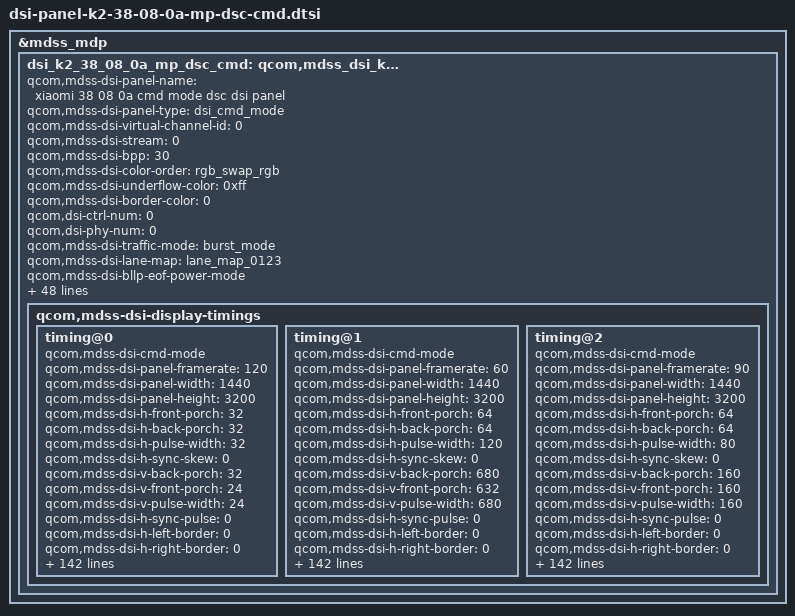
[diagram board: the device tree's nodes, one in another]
&mdss_mdp {
	dsi_k2_38_08_0a_mp_dsc_cmd: qcom,mdss_dsi_k2_38_08_0a_mp_dsc_cmd {
		qcom,mdss-dsi-panel-name = "xiaomi 38 08 0a cmd mode dsc dsi panel";
		qcom,mdss-dsi-panel-type = "dsi_cmd_mode";
		qcom,mdss-dsi-virtual-channel-id = <0>;
		qcom,mdss-dsi-stream = <0>;
		qcom,mdss-dsi-bpp = <30>;
		qcom,mdss-dsi-color-order = "rgb_swap_rgb";
		qcom,mdss-dsi-underflow-color = <0xff>;
		qcom,mdss-dsi-border-color = <0>;

		qcom,dsi-ctrl-num = <0>;
		qcom,dsi-phy-num = <0>;

		qcom,mdss-dsi-traffic-mode = "burst_mode";
		qcom,mdss-dsi-lane-map = "lane_map_0123";
		qcom,mdss-dsi-bllp-eof-power-mode;
		qcom,mdss-dsi-bllp-power-mode;
		qcom,mdss-dsi-lane-0-state;
		qcom,mdss-dsi-lane-1-state;
		qcom,mdss-dsi-lane-2-state;
		qcom,mdss-dsi-lane-3-state;
		qcom,mdss-dsi-dma-trigger = "trigger_sw";
		qcom,mdss-dsi-mdp-trigger = "none";
		qcom,mdss-dsi-reset-sequence = <0 10>, <1 10>;
		qcom,mdss-pan-physical-width-dimension = <710>;
		qcom,mdss-pan-physical-height-dimension = <1578>;
		qcom,mdss-dsi-te-pin-select = <1>;
		qcom,mdss-dsi-wr-mem-start = <0x2c>;
		qcom,mdss-dsi-wr-mem-continue = <0x3c>;
		qcom,mdss-dsi-te-dcs-command = <1>;
		qcom,mdss-dsi-te-check-enable;
		qcom,mdss-dsi-te-using-te-pin;
		qcom,mdss-dsi-tx-eot-append;
		qcom,mdss-dsi-lp11-init;

		qcom,mdss-dsi-panel-mode-switch;

		qcom,mdss-dsi-bl-inverted-dbv;
		qcom,bl-update-flag = "delay_until_first_frame";

		qcom,mdss-dsi-panel-hdr-enabled;
		qcom,mdss-dsi-panel-hdr-color-primaries = <14500 15500 32000
			17000 15500 30000 8000 3000>;
		qcom,mdss-dsi-panel-peak-brightness = <4200000>;
		qcom,mdss-dsi-panel-blackness-level = <3230>;

		qcom,mdss-dsi-display-timings {
			timing@0{
				qcom,mdss-dsi-cmd-mode;
				qcom,mdss-dsi-panel-framerate = <120>;
				qcom,mdss-dsi-panel-width = <1440>;
				qcom,mdss-dsi-panel-height = <3200>;
				qcom,mdss-dsi-h-front-porch = <32>;
				qcom,mdss-dsi-h-back-porch = <32>;
				qcom,mdss-dsi-h-pulse-width = <32>;
				qcom,mdss-dsi-h-sync-skew = <0>;
				qcom,mdss-dsi-v-back-porch = <32>;
				qcom,mdss-dsi-v-front-porch = <24>;
				qcom,mdss-dsi-v-pulse-width = <24>;
				qcom,mdss-dsi-h-sync-pulse = <0>;
				qcom,mdss-dsi-h-left-border = <0>;
				qcom,mdss-dsi-h-right-border = <0>;
				qcom,mdss-dsi-v-top-border = <0>;
				qcom,mdss-dsi-v-bottom-border = <0>;
				qcom,mdss-dsi-panel-clockrate = <1360000000>;
				qcom,mdss-dsi-panel-jitter = <0x5 0x1>;
				qcom,mdss-mdp-transfer-time-us = <6800>;
				qcom,mdss-dsi-on-command = [
					/* 1 DSC Setting */
					15 01 00 00 00 00 02 9D 01                           /* Compression Enable */
					39 01 00 00 00 00 81 9E                              /* PPS Setting */
					11 00 00 A9 30 80 0C 80
					05 A0 00 32 02 D0 02 D0
					02 00 02 68 00 20 05 8C
					00 0A 00 0C 01 F6 01 87
					18 00 10 F0 03 0C 20 00
					06 0B 0B 33 0E 1C 2A 38
					46 54 62 69 70 77 79 7B
					7D 7E 01 02 01 00 09 40
					09 BE 19 FC 19 FA 19 F8
					1A 38 1A 78 1A B6 2A F6
					2B 34 2B 74 3B 74 6B F4
					00 00 00 00 00 00 00 00
					00 00 00 00 00 00 00 00
					00 00 00 00 00 00 00 00
					00 00 00 00 00 00 00 00
					00 00 00 00 00 00 00 00
					/* 2 Sleep Out */
					05 01 00 00 0A 00 02 11 00                           /* Sleep Out */
					/* 3 Common Setting */
					/* 3.1 TE(Vsync) On/Off */
					15 01 00 00 00 00 02 35 00                           /* TE On(Vsync) */
					/* 3.2 CASET/PASET Setting */
					39 01 00 00 00 00 05 2A 00 00 05 9F                  /* CASET 1440*/
					39 01 00 00 00 00 05 2B 00 00 0C 7F                  /* PASET 3200*/
					/* 4.3 11Bit Dimming Setting */
					39 01 00 00 00 00 03 F0 5A 5A
					15 01 00 00 00 00 02 B0 01                           /* Global para */
					15 01 00 00 00 00 02 B4 01                           /* 11Bit Dimming On*/
					15 01 00 00 00 00 02 F7 07                           /* Update Key*/
					39 01 00 00 00 00 03 F0 A5 A5
					/* 4.8 Err FG Setting*/
					39 01 00 00 00 00 03 F0 5A 5A
					15 01 00 00 00 00 02 B0 02
					39 01 00 00 00 00 05 F4 00 C0 7F 3D
					15 01 00 00 00 00 02 B0 09
					15 01 00 00 00 00 02 F4 07
					15 01 00 00 00 00 02 B0 11
					15 01 00 00 00 00 02 F4 19
					39 01 00 00 00 00 03 F0 A5 A5
					/* AOD Setting*/
					39 01 00 00 00 00 03 F0 5A 5A
					15 01 00 00 00 00 02 B0 04
					15 01 00 00 00 00 02 EE 80
					15 01 00 00 00 00 02 B0 C0
					15 01 00 00 00 00 02 D6 40
					39 01 00 00 00 00 03 F0 A5 A5
					/* 4.10 Pentile Setting*/
					39 01 00 00 00 00 03 F0 5A 5A
					39 01 00 00 00 00 08 B3 00 00 D8 D8 FF FF 40         /* 2D Rendering */
					39 01 00 00 00 00 03 F0 A5 A5
					/* DCDC SET PIN LOW*/
					39 01 00 00 00 00 03 F0 5A 5A
					15 01 00 00 00 00 02 E7 81
					15 01 00 00 00 00 02 B0 09
					15 01 00 00 00 00 02 E7 03
					39 01 00 00 00 00 03 F0 A5 A5
					/* SRAM ECC ON*/
					39 01 00 00 00 00 03 F0 5A 5A
					39 01 00 00 00 00 03 FC 5A 5A
					39 01 00 00 00 00 02 B0 0F
					39 01 00 00 00 00 02 E1 10
					/* OPEC IP Bypass*/
					39 01 00 00 00 00 02 CF 01
					39 01 00 00 00 00 03 FC A5 A5
					39 01 00 00 00 00 03 F0 A5 A5
					/* 4.11 Power Saving Setting*/
					39 01 00 00 00 00 03 F0 5A 5A
					39 01 00 00 00 00 03 FC 5A 5A
					15 01 00 00 00 00 02 B0 76
					15 01 00 00 00 00 02 D1 01
					15 01 00 00 00 00 02 B0 22
					39 01 00 00 00 00 04 E2 01 02 25
					15 01 00 00 00 00 02 F7 07
					39 01 00 00 00 00 03 FC A5 A5
					39 01 00 00 5A 00 03 F0 A5 A5
					/* Dimming Setting*/
					39 01 00 00 00 00 03 F0 5A 5A
					15 01 00 00 00 00 02 B0 0D                           /* Global para */
					15 01 00 00 00 00 02 B4 20                           /* Dimming Speed Setting : 0x20 : 32Frames*/
					15 01 00 00 00 00 02 B0 0C                           /* Global para */
					15 01 00 00 00 00 02 B4 20                           /* 0x20 : ELVSS DIM OFF */
					15 01 00 00 00 00 02 53 20                           /* 0x20 Normal transition(60Hz) */
					39 01 00 00 00 00 03 51 00 00                        /* Write Display Brightness */
					15 01 00 00 00 00 02 F7 07
					39 01 00 00 00 00 03 F0 A5 A5
					/* OFC (MIPI 1360Mbps/Lane, OSC 165Mhz)*/
					39 01 00 00 00 00 03 F0 5A 5A
					39 01 00 00 00 00 03 FC 5A 5A
					15 01 00 00 00 00 02 B0 07
					39 01 00 00 00 00 04 EB 03 88 F8
					39 01 00 00 00 00 03 FC A5 A5
					39 01 00 00 00 00 03 F0 A5 A5
					/* 5 Display On */
					05 01 00 00 11 00 02 29 00
					/* 120hz Frequency Select*/
					15 01 00 00 00 00 02 60 08
					39 01 00 00 00 00 03 F0 5A 5A
					39 01 00 00 00 00 03 FC 5A 5A
					15 01 00 00 00 00 02 B0 55
					15 01 00 00 00 00 02 D1 0E
					15 01 00 00 00 00 02 F7 07
					39 01 00 00 00 00 03 FC A5 A5
					39 01 00 00 00 00 03 F0 A5 A5];
				qcom,mdss-dsi-off-command = [
					39 00 00 00 00 00 03 F0 5A 5A
					39 00 00 00 00 00 03 FC 5A 5A
					15 00 00 00 00 00 02 60 08
					15 00 00 00 00 00 02 B0 55
					15 00 00 00 00 00 02 D1 0E
					15 00 00 00 00 00 02 53 28
					15 00 00 00 00 00 02 F7 07
					39 00 00 00 00 00 03 FC A5 A5
					39 01 00 00 00 00 03 F0 A5 A5
					05 01 00 00 22 00 02 28 00
					05 01 00 00 78 00 02 10 00];
				qcom,mdss-dsi-on-command-state = "dsi_lp_mode";
				qcom,mdss-dsi-off-command-state = "dsi_lp_mode";

				qcom,mdss-dsi-timing-switch-command = [
					15 00 00 00 00 00 02 60 08
					39 00 00 00 00 00 03 F0 5A 5A
					39 00 00 00 00 00 03 FC 5A 5A
					15 00 00 00 00 00 02 B0 55
					15 00 00 00 00 00 02 D1 0E
					15 00 00 00 00 00 02 F7 07
					39 00 00 00 00 00 03 FC A5 A5
					39 01 00 00 00 00 03 F0 A5 A5];
				qcom,mdss-dsi-timing-switch-command-state = "dsi_lp_mode";

				qcom,mdss-dsi-nolp-command = [
					39 01 00 00 00 00 03 F0 5A 5A
					39 01 00 00 00 00 03 FC 5A 5A
					15 00 00 00 00 00 02 60 08
					15 00 00 00 00 00 02 B0 55
					15 00 00 00 00 00 02 D1 0E
					15 00 00 00 00 00 02 53 28
					15 01 00 00 00 00 02 F7 07
					39 01 00 00 00 00 03 FC A5 A5
					39 01 00 00 09 00 03 F0 A5 A5
				];
				qcom,mdss-dsi-nolp-command-state = "dsi_lp_mode";

				qcom,compression-mode = "dsc";
				qcom,mdss-dsc-slice-height = <50>;
				qcom,mdss-dsc-slice-width = <720>;
				qcom,mdss-dsc-slice-per-pkt = <2>;
				qcom,mdss-dsc-bit-per-component = <10>;
				qcom,mdss-dsc-bit-per-pixel = <8>;
				qcom,mdss-dsc-block-prediction-enable;
			};

			timing@1{
				qcom,mdss-dsi-cmd-mode;
				qcom,mdss-dsi-panel-framerate = <60>;
				qcom,mdss-dsi-panel-width = <1440>;
				qcom,mdss-dsi-panel-height = <3200>;
				qcom,mdss-dsi-h-front-porch = <64>;
				qcom,mdss-dsi-h-back-porch = <64>;
				qcom,mdss-dsi-h-pulse-width = <120>;
				qcom,mdss-dsi-h-sync-skew = <0>;
				qcom,mdss-dsi-v-back-porch = <680>;
				qcom,mdss-dsi-v-front-porch = <632>;
				qcom,mdss-dsi-v-pulse-width = <680>;
				qcom,mdss-dsi-h-sync-pulse = <0>;
				qcom,mdss-dsi-h-left-border = <0>;
				qcom,mdss-dsi-h-right-border = <0>;
				qcom,mdss-dsi-v-top-border = <0>;
				qcom,mdss-dsi-v-bottom-border = <0>;
				qcom,mdss-dsi-panel-clockrate = <1360000000>;
				qcom,mdss-dsi-panel-jitter = <0x5 0x1>;
				qcom,mdss-mdp-transfer-time-us = <14000>;
				qcom,mdss-dsi-on-command = [
					/* 1 DSC Setting */
					15 01 00 00 00 00 02 9D 01                           /* Compression Enable */
					39 01 00 00 00 00 81 9E                              /* PPS Setting */
					11 00 00 A9 30 80 0C 80
					05 A0 00 32 02 D0 02 D0
					02 00 02 68 00 20 05 8C
					00 0A 00 0C 01 F6 01 87
					18 00 10 F0 03 0C 20 00
					06 0B 0B 33 0E 1C 2A 38
					46 54 62 69 70 77 79 7B
					7D 7E 01 02 01 00 09 40
					09 BE 19 FC 19 FA 19 F8
					1A 38 1A 78 1A B6 2A F6
					2B 34 2B 74 3B 74 6B F4
					00 00 00 00 00 00 00 00
					00 00 00 00 00 00 00 00
					00 00 00 00 00 00 00 00
					00 00 00 00 00 00 00 00
					00 00 00 00 00 00 00 00
					/* 2 Sleep Out */
					05 01 00 00 0A 00 02 11 00                           /* Sleep Out */
					/* 3 Common Setting */
					/* 3.1 TE(Vsync) On/Off */
					15 01 00 00 00 00 02 35 00                           /* TE On(Vsync) */
					/* 3.2 CASET/PASET Setting */
					39 01 00 00 00 00 05 2A 00 00 05 9F                  /* CASET 1440*/
					39 01 00 00 00 00 05 2B 00 00 0C 7F                  /* PASET 3200*/
					/* 4.3 11Bit Dimming Setting */
					39 01 00 00 00 00 03 F0 5A 5A
					15 01 00 00 00 00 02 B0 01                           /* Global para */
					15 01 00 00 00 00 02 B4 01                           /* 11Bit Dimming On*/
					15 01 00 00 00 00 02 F7 07                           /* Update Key*/
					39 01 00 00 00 00 03 F0 A5 A5
					/* 4.8 Err FG Setting*/
					39 01 00 00 00 00 03 F0 5A 5A
					15 01 00 00 00 00 02 B0 02
					39 01 00 00 00 00 05 F4 00 C0 7F 3D
					15 01 00 00 00 00 02 B0 09
					15 01 00 00 00 00 02 F4 07
					15 01 00 00 00 00 02 B0 11
					15 01 00 00 00 00 02 F4 19
					39 01 00 00 00 00 03 F0 A5 A5
					/* AOD Setting*/
					39 01 00 00 00 00 03 F0 5A 5A
					15 01 00 00 00 00 02 B0 04
					15 01 00 00 00 00 02 EE 80
					15 01 00 00 00 00 02 B0 C0
					15 01 00 00 00 00 02 D6 40
					39 01 00 00 00 00 03 F0 A5 A5
					/* 4.10 Pentile Setting*/
					39 01 00 00 00 00 03 F0 5A 5A
					39 01 00 00 00 00 08 B3 00 00 D8 D8 FF FF 40         /* 2D Rendering */
					39 01 00 00 00 00 03 F0 A5 A5
					/* DCDC SET PIN LOW*/
					39 01 00 00 00 00 03 F0 5A 5A
					15 01 00 00 00 00 02 E7 81
					15 01 00 00 00 00 02 B0 09
					15 01 00 00 00 00 02 E7 03
					39 01 00 00 00 00 03 F0 A5 A5
					/* SRAM ECC ON*/
					39 01 00 00 00 00 03 F0 5A 5A
					39 01 00 00 00 00 03 FC 5A 5A
					39 01 00 00 00 00 02 B0 0F
					39 01 00 00 00 00 02 E1 10
					/* OPEC IP Bypass*/
					39 01 00 00 00 00 02 CF 01
					39 01 00 00 00 00 03 FC A5 A5
					39 01 00 00 00 00 03 F0 A5 A5
					/* 4.11 Power Saving Setting*/
					39 01 00 00 00 00 03 F0 5A 5A
					39 01 00 00 00 00 03 FC 5A 5A
					15 01 00 00 00 00 02 B0 76
					15 01 00 00 00 00 02 D1 01
					15 01 00 00 00 00 02 B0 22
					39 01 00 00 00 00 04 E2 01 02 25
					15 01 00 00 00 00 02 F7 07
					39 01 00 00 00 00 03 FC A5 A5
					39 01 00 00 5A 00 03 F0 A5 A5
					/* Dimming Setting*/
					39 01 00 00 00 00 03 F0 5A 5A
					15 01 00 00 00 00 02 B0 0D                           /* Global para */
					15 01 00 00 00 00 02 B4 20                           /* Dimming Speed Setting : 0x20 : 32Frames*/
					15 01 00 00 00 00 02 B0 0C                           /* Global para */
					15 01 00 00 00 00 02 B4 20                           /* 0x20 : ELVSS DIM OFF */
					15 01 00 00 00 00 02 53 20                           /* 0x20 Normal transition(60Hz) */
					39 01 00 00 00 00 03 51 00 00                        /* Write Display Brightness */
					15 01 00 00 00 00 02 F7 07
					39 01 00 00 00 00 03 F0 A5 A5
					/* OFC (MIPI 1360Mbps/Lane, OSC 165Mhz)*/
					39 01 00 00 00 00 03 F0 5A 5A
					39 01 00 00 00 00 03 FC 5A 5A
					15 01 00 00 00 00 02 B0 07
					39 01 00 00 00 00 04 EB 03 88 F8
					39 01 00 00 00 00 03 FC A5 A5
					39 01 00 00 00 00 03 F0 A5 A5
					/* 5 Display On */
					05 01 00 00 11 00 02 29 00
					/* 60hz Frequency Select*/
					15 01 00 00 00 00 02 60 00
					39 01 00 00 00 00 03 F0 5A 5A
					39 01 00 00 00 00 03 FC 5A 5A
					15 01 00 00 00 00 02 B0 55
					15 01 00 00 00 00 02 D1 0E
					15 01 00 00 00 00 02 F7 07
					39 01 00 00 00 00 03 FC A5 A5
					39 01 00 00 00 00 03 F0 A5 A5];
				qcom,mdss-dsi-off-command = [
					39 00 00 00 00 00 03 F0 5A 5A
					39 00 00 00 00 00 03 FC 5A 5A
					15 00 00 00 00 00 02 60 00
					15 00 00 00 00 00 02 B0 55
					15 00 00 00 00 00 02 D1 0E
					15 00 00 00 00 00 02 53 28
					15 00 00 00 00 00 02 F7 07
					39 00 00 00 00 00 03 FC A5 A5
					39 01 00 00 00 00 03 F0 A5 A5
					05 01 00 00 22 00 02 28 00
					05 01 00 00 78 00 02 10 00];
				qcom,mdss-dsi-on-command-state = "dsi_lp_mode";
				qcom,mdss-dsi-off-command-state = "dsi_lp_mode";

				qcom,mdss-dsi-timing-switch-command = [
					15 00 00 00 00 00 02 60 00
					39 00 00 00 00 00 03 F0 5A 5A
					39 00 00 00 00 00 03 FC 5A 5A
					15 00 00 00 00 00 02 B0 55
					15 00 00 00 00 00 02 D1 0E
					15 00 00 00 00 00 02 F7 07
					39 00 00 00 00 00 03 FC A5 A5
					39 01 00 00 11 00 03 F0 A5 A5];
				qcom,mdss-dsi-timing-switch-command-state = "dsi_lp_mode";

				qcom,mdss-dsi-nolp-command = [
					39 01 00 00 00 00 03 F0 5A 5A
					39 01 00 00 00 00 03 FC 5A 5A
					15 00 00 00 00 00 02 60 00
					15 00 00 00 00 00 02 B0 55
					15 00 00 00 00 00 02 D1 0E
					15 00 00 00 00 00 02 53 28
					15 01 00 00 00 00 02 F7 07
					39 01 00 00 00 00 03 FC A5 A5
					39 01 00 00 09 00 03 F0 A5 A5
				];
				qcom,mdss-dsi-nolp-command-state = "dsi_lp_mode";

				qcom,compression-mode = "dsc";
				qcom,mdss-dsc-slice-height = <50>;
				qcom,mdss-dsc-slice-width = <720>;
				qcom,mdss-dsc-slice-per-pkt = <2>;
				qcom,mdss-dsc-bit-per-component = <10>;
				qcom,mdss-dsc-bit-per-pixel = <8>;
				qcom,mdss-dsc-block-prediction-enable;
			};

			timing@2{
				qcom,mdss-dsi-cmd-mode;
				qcom,mdss-dsi-panel-framerate = <90>;
				qcom,mdss-dsi-panel-width = <1440>;
				qcom,mdss-dsi-panel-height = <3200>;
				qcom,mdss-dsi-h-front-porch = <64>;
				qcom,mdss-dsi-h-back-porch = <64>;
				qcom,mdss-dsi-h-pulse-width = <80>;
				qcom,mdss-dsi-h-sync-skew = <0>;
				qcom,mdss-dsi-v-back-porch = <160>;
				qcom,mdss-dsi-v-front-porch = <160>;
				qcom,mdss-dsi-v-pulse-width = <160>;
				qcom,mdss-dsi-h-sync-pulse = <0>;
				qcom,mdss-dsi-h-left-border = <0>;
				qcom,mdss-dsi-h-right-border = <0>;
				qcom,mdss-dsi-v-top-border = <0>;
				qcom,mdss-dsi-v-bottom-border = <0>;
				qcom,mdss-dsi-panel-clockrate = <1360000000>;
				qcom,mdss-dsi-panel-jitter = <0x5 0x1>;
				qcom,mdss-mdp-transfer-time-us = <9500>;
				qcom,mdss-dsi-on-command = [
					/* 1 DSC Setting */
					15 01 00 00 00 00 02 9D 01                           /* Compression Enable */
					39 01 00 00 00 00 81 9E                              /* PPS Setting */
					11 00 00 A9 30 80 0C 80
					05 A0 00 32 02 D0 02 D0
					02 00 02 68 00 20 05 8C
					00 0A 00 0C 01 F6 01 87
					18 00 10 F0 03 0C 20 00
					06 0B 0B 33 0E 1C 2A 38
					46 54 62 69 70 77 79 7B
					7D 7E 01 02 01 00 09 40
					09 BE 19 FC 19 FA 19 F8
					1A 38 1A 78 1A B6 2A F6
					2B 34 2B 74 3B 74 6B F4
					00 00 00 00 00 00 00 00
					00 00 00 00 00 00 00 00
					00 00 00 00 00 00 00 00
					00 00 00 00 00 00 00 00
					00 00 00 00 00 00 00 00
					/* 2 Sleep Out */
					05 01 00 00 0A 00 02 11 00                           /* Sleep Out */
					/* 3 Common Setting */
					/* 3.1 TE(Vsync) On/Off */
					15 01 00 00 00 00 02 35 00                           /* TE On(Vsync) */
					/* 3.2 CASET/PASET Setting */
					39 01 00 00 00 00 05 2A 00 00 05 9F                  /* CASET 1440*/
					39 01 00 00 00 00 05 2B 00 00 0C 7F                  /* PASET 3200*/
					/* 4.3 11Bit Dimming Setting */
					39 01 00 00 00 00 03 F0 5A 5A
					15 01 00 00 00 00 02 B0 01                           /* Global para */
					15 01 00 00 00 00 02 B4 01                           /* 11Bit Dimming On*/
					15 01 00 00 00 00 02 F7 07                           /* Update Key*/
					39 01 00 00 00 00 03 F0 A5 A5
					/* 4.8 Err FG Setting*/
					39 01 00 00 00 00 03 F0 5A 5A
					15 01 00 00 00 00 02 B0 02
					39 01 00 00 00 00 05 F4 00 C0 7F 3D
					15 01 00 00 00 00 02 B0 09
					15 01 00 00 00 00 02 F4 07
					15 01 00 00 00 00 02 B0 11
					15 01 00 00 00 00 02 F4 19
					39 01 00 00 00 00 03 F0 A5 A5
					/* AOD Setting*/
					39 01 00 00 00 00 03 F0 5A 5A
					15 01 00 00 00 00 02 B0 04
					15 01 00 00 00 00 02 EE 80
					15 01 00 00 00 00 02 B0 C0
					15 01 00 00 00 00 02 D6 40
					39 01 00 00 00 00 03 F0 A5 A5
					/* 4.10 Pentile Setting*/
					39 01 00 00 00 00 03 F0 5A 5A
					39 01 00 00 00 00 08 B3 00 00 D8 D8 FF FF 40         /* 2D Rendering */
					39 01 00 00 00 00 03 F0 A5 A5
					/* DCDC SET PIN LOW*/
					39 01 00 00 00 00 03 F0 5A 5A
					15 01 00 00 00 00 02 E7 81
					15 01 00 00 00 00 02 B0 09
					15 01 00 00 00 00 02 E7 03
					39 01 00 00 00 00 03 F0 A5 A5
					/* SRAM ECC ON*/
					39 01 00 00 00 00 03 F0 5A 5A
					39 01 00 00 00 00 03 FC 5A 5A
					39 01 00 00 00 00 02 B0 0F
					39 01 00 00 00 00 02 E1 10
					/* OPEC IP Bypass*/
					39 01 00 00 00 00 02 CF 01
					39 01 00 00 00 00 03 FC A5 A5
					39 01 00 00 00 00 03 F0 A5 A5
					/* 4.11 Power Saving Setting*/
					39 01 00 00 00 00 03 F0 5A 5A
					39 01 00 00 00 00 03 FC 5A 5A
					15 01 00 00 00 00 02 B0 76
					15 01 00 00 00 00 02 D1 01
					15 01 00 00 00 00 02 B0 22
					39 01 00 00 00 00 04 E2 01 02 25
					15 01 00 00 00 00 02 F7 07
					39 01 00 00 00 00 03 FC A5 A5
					39 01 00 00 5A 00 03 F0 A5 A5
					/* Dimming Setting*/
					39 01 00 00 00 00 03 F0 5A 5A
					15 01 00 00 00 00 02 B0 0D                           /* Global para */
					15 01 00 00 00 00 02 B4 20                           /* Dimming Speed Setting : 0x20 : 32Frames*/
					15 01 00 00 00 00 02 B0 0C                           /* Global para */
					15 01 00 00 00 00 02 B4 20                           /* 0x20 : ELVSS DIM OFF */
					15 01 00 00 00 00 02 53 20                           /* 0x20 Normal transition(60Hz) */
					39 01 00 00 00 00 03 51 00 00                        /* Write Display Brightness */
					15 01 00 00 00 00 02 F7 07
					39 01 00 00 00 00 03 F0 A5 A5
					/* OFC (MIPI 1360Mbps/Lane, OSC 165Mhz)*/
					39 01 00 00 00 00 03 F0 5A 5A
					39 01 00 00 00 00 03 FC 5A 5A
					15 01 00 00 00 00 02 B0 07
					39 01 00 00 00 00 04 EB 03 88 F8
					39 01 00 00 00 00 03 FC A5 A5
					39 01 00 00 00 00 03 F0 A5 A5
					/* 5 Display On */
					05 01 00 00 11 00 02 29 00
					/* 90hz Frequency Select*/
					15 01 00 00 00 00 02 60 08
					39 01 00 00 00 00 03 F0 5A 5A
					39 01 00 00 00 00 03 FC 5A 5A
					15 01 00 00 00 00 02 B0 55
					15 01 00 00 00 00 02 D1 53
					15 01 00 00 00 00 02 F7 07
					39 01 00 00 00 00 03 FC A5 A5
					39 01 00 00 00 00 03 F0 A5 A5];
				qcom,mdss-dsi-off-command = [
					39 00 00 00 00 00 03 F0 5A 5A
					39 00 00 00 00 00 03 FC 5A 5A
					15 00 00 00 00 00 02 60 08
					15 00 00 00 00 00 02 B0 55
					15 00 00 00 00 00 02 D1 53
					15 00 00 00 00 00 02 53 28
					15 00 00 00 00 00 02 F7 07
					39 00 00 00 00 00 03 FC A5 A5
					39 01 00 00 00 00 03 F0 A5 A5
					05 01 00 00 22 00 02 28 00
					05 01 00 00 78 00 02 10 00];
				qcom,mdss-dsi-on-command-state = "dsi_lp_mode";
				qcom,mdss-dsi-off-command-state = "dsi_lp_mode";

				qcom,mdss-dsi-timing-switch-command = [
					/* 90hz Frequency Select*/
					15 00 00 00 00 00 02 60 08
					39 00 00 00 00 00 03 F0 5A 5A
					39 00 00 00 00 00 03 FC 5A 5A
					15 00 00 00 00 00 02 B0 55
					15 00 00 00 00 00 02 D1 53
					15 00 00 00 00 00 02 F7 07
					39 00 00 00 00 00 03 FC A5 A5
					39 01 00 00 11 00 03 F0 A5 A5];
				qcom,mdss-dsi-timing-switch-command-state = "dsi_lp_mode";

				qcom,mdss-dsi-nolp-command = [
					39 01 00 00 00 00 03 F0 5A 5A
					39 01 00 00 00 00 03 FC 5A 5A
					15 00 00 00 00 00 02 60 08
					15 00 00 00 00 00 02 B0 55
					15 00 00 00 00 00 02 D1 53
					15 00 00 00 00 00 02 53 28
					15 01 00 00 00 00 02 F7 07
					39 01 00 00 00 00 03 FC A5 A5
					39 01 00 00 09 00 03 F0 A5 A5
				];
				qcom,mdss-dsi-nolp-command-state = "dsi_lp_mode";

				qcom,compression-mode = "dsc";
				qcom,mdss-dsc-slice-height = <50>;
				qcom,mdss-dsc-slice-width = <720>;
				qcom,mdss-dsc-slice-per-pkt = <2>;
				qcom,mdss-dsc-bit-per-component = <10>;
				qcom,mdss-dsc-bit-per-pixel = <8>;
				qcom,mdss-dsc-block-prediction-enable;
			};
		};
	};
};

&dsi_k2_38_08_0a_mp_dsc_cmd{
	mi,panel-id = <0x4A32 0x00380800>;
	mi,hbm-51-ctl-flag;
	mi,hbm-off-51-index = <2>;
	mi,hbm-on-51-index = <2>;
	//mi,delay-before-fod-hbm-off;
	//mi,delay-before-fod-hbm-on;
	mi,hbm-fod-off-51-index = <2>;
	mi,hbm-fod-on-51-index = <2>;
	mi,hbm-fod-bl-level = <2047>;
	mi,hbm-bl-min-level = <1>;
	mi,hbm-bl-max-level = <2047>;

	mi,esd-err-irq-gpio = <&tlmm 75 0x2001>;

	mi,panel-on-dimming-delay = <120>;

	/* Nolp code customized*/
	mi,aod-nolp-command-enabled;

	mi,mdss-dsi-panel-dc-threshold = <440>;

	mi,max-brightness-clone = <8191>;

	mi,local-hbm-enabled;
	mi,local-hbm-on-1000nit-51-index = <3>;
	mi,local-hbm-off-to-hbm-51-index = <2>;
	mi,doze-hbm-dbv-level = <196>;
	mi,doze-lbm-dbv-level = <22>;

	mi,fod-low-brightness-clone-threshold = <35>;
	mi,fod-low-brightness-lux-threshold = <1>;
	mi,mdss-dsi-panel-hbm-brightness = <1>;

	qcom,mdss-dsi-display-timings {
		timing@0{
			mi,mdss-dsi-dimmingon-command = [15 01 00 00 00 00 02 53 28];
			mi,mdss-dsi-dimmingon-command-state = "dsi_hs_mode";
			mi,mdss-dsi-dimmingoff-command = [15 01 00 00 00 00 02 53 20];
			mi,mdss-dsi-dimmingoff-command-state = "dsi_hs_mode";

			mi,mdss-dsi-hbm-on-command = [
				39 01 00 00 00 00 03 F0 5A 5A
				15 00 00 00 00 00 02 53 E8
				39 00 00 00 00 00 03 51 00 00
				15 01 00 00 00 00 02 F7 07
				39 01 00 00 00 00 03 F0 A5 A5
			];
			mi,mdss-dsi-hbm-off-command = [
				39 01 00 00 00 00 03 F0 5A 5A
				15 00 00 00 00 00 02 53 28
				39 00 00 00 00 00 03 51 07 FF
				15 01 00 00 00 00 02 F7 07
				39 01 00 00 00 00 03 F0 A5 A5
			];
			mi,mdss-dsi-hbm-on-command-state = "dsi_lp_mode";
			mi,mdss-dsi-hbm-off-command-state = "dsi_lp_mode";

			mi,mdss-dsi-hbm-fod-on-command = [
				39 01 00 00 00 00 03 F0 5A 5A
				/* HBM On */
				15 00 00 00 00 00 02 53 E0
				39 00 00 00 00 00 03 51 07 FF
				15 01 00 00 00 00 02 F7 07
				39 01 00 00 09 00 03 F0 A5 A5
			];
			mi,mdss-dsi-hbm-fod-off-command = [
				39 01 00 00 00 00 03 F0 5A 5A
				/* HBM off*/
				15 00 00 00 00 00 02 53 20
				39 00 00 00 00 00 03 51 07 FF
				15 01 00 00 00 00 02 F7 07
				39 01 00 00 09 00 03 F0 A5 A5
			];
			mi,mdss-dsi-hbm-fod-on-command-state = "dsi_lp_mode";
			mi,mdss-dsi-hbm-fod-off-command-state = "dsi_lp_mode";

			mi,mdss-dsi-doze-hbm-command = [
				39 01 00 00 00 00 03 F0 5A 5A
				15 00 00 00 00 00 02 53 24
				15 01 00 00 00 00 02 F7 07
				39 01 00 00 00 00 03 F0 A5 A5
			];

			mi,mdss-dsi-doze-lbm-command = [
				39 01 00 00 00 00 03 F0 5A 5A
				15 00 00 00 00 00 02 53 25
				15 01 00 00 00 00 02 F7 07
				39 01 00 00 00 00 03 F0 A5 A5
			];
			mi,mdss-dsi-doze-hbm-command-state = "dsi_lp_mode";
			mi,mdss-dsi-doze-lbm-command-state = "dsi_lp_mode";

			mi,mdss-dsi-doze-hbm-nolp-command = [
				39 00 00 00 00 00 03 F0 5A 5A
				39 00 00 00 00 00 03 FC 5A 5A
				15 00 00 00 00 00 02 60 08
				15 00 00 00 00 00 02 B0 55
				15 00 00 00 00 00 02 D1 0E
				15 00 00 00 00 00 02 53 28
				15 00 00 00 00 00 02 F7 07
				39 00 00 00 00 00 03 FC A5 A5
				39 01 00 00 00 00 03 F0 A5 A5
			];
			mi,mdss-dsi-doze-hbm-nolp-command-state = "dsi_lp_mode";
			mi,mdss-dsi-doze-lbm-nolp-command = [
				39 00 00 00 00 00 03 F0 5A 5A
				39 00 00 00 00 00 03 FC 5A 5A
				15 00 00 00 00 00 02 60 08
				15 00 00 00 00 00 02 B0 55
				15 00 00 00 00 00 02 D1 0E
				15 00 00 00 00 00 02 53 29
				15 00 00 00 00 00 02 F7 07
				39 00 00 00 00 00 03 FC A5 A5
				39 01 00 00 00 00 03 F0 A5 A5
			];
			mi,mdss-dsi-doze-lbm-nolp-command-state = "dsi_lp_mode";

			mi,mdss-dsi-flat-mode-on-command = [
				39 01 00 00 00 00 03 F0 5A 5A
				39 00 00 00 00 00 29 C6
				37 21 8D FF 55 86 00 B0
				0E FF FF 0E FF 80 91 13
				0F 0F 0F 3D 3D 3D 51 51
				51 60 60 60 66 66 66 A4
				E4 A4 08 00 80 00 00 22
				15 01 00 00 00 00 02 F7 07
				39 01 00 00 09 00 03 F0 A5 A5

			];
			mi,mdss-dsi-nature-flat-mode-on-command = [
				39 01 00 00 00 00 03 F0 5A 5A
				39 01 00 00 00 00 29 C6 37 21 E1 FF
				67 86 00 B0 0E FF FF 0E FF 80 91 13
				0E 0F 0E 3B 3D 38 4F 51 4B 5E 60 59
				63 66 5E A4 E4 A4 08 00 80 00 00 22
				39 01 00 00 00 00 02 B0 CD
				39 01 00 00 00 00 0F D3 E2 06 06 06
				92 2C 6A 80 5F 4C 40 33 FF 90
				39 01 00 00 00 00 02 F7 07
			];
			mi,mdss-dsi-flat-mode-off-command = [
				39 01 00 00 00 00 03 F0 5A 5A
				39 00 00 00 00 00 29 C6
				37 01 8D FF 55 86 00 B0
				0E FF FF 0E FF 80 91 13
				0F 0F 0F 3D 3D 3D 51 51
				51 60 60 60 66 66 66 A4
				E4 A4 08 00 80 00 00 22
				15 01 00 00 00 00 02 F7 07
				39 01 00 00 09 00 03 F0 A5 A5

			];
			mi,mdss-dsi-nature-flat-mode-off-command = [
				39 01 00 00 00 00 03 F0 5A 5A
				39 01 00 00 00 00 29 C6 37 01 E1 FF
				67 86 00 B0 0E FF FF 0E FF 80 91 13
				0E 0F 0E 3B 3D 38 4F 51 4B 5E 60 59
				63 66 5E A4 E4 A4 08 00 80 00 00 22
				39 01 00 00 00 00 02 B0 CD
				39 01 00 00 00 00 02 D3 00
				39 01 00 00 00 00 02 F7 07
			];
			mi,mdss-dsi-flat-mode-on-command-state = "dsi_lp_mode";
			mi,mdss-dsi-nature-flat-mode-on-command-state = "dsi_lp_mode";
			mi,mdss-dsi-flat-mode-off-command-state = "dsi_lp_mode";
			mi,mdss-dsi-nature-flat-mode-off-command-state = "dsi_lp_mode";
			mi,mdss-dsi-crc-off-command = [
				/* CRC Disable (Normal mode) */
				39 01 00 00 00 00 02 80 00
				39 00 00 00 00 00 03 F0 5A 5A
				/* CRC Bypass */
				39 00 00 00 00 00 02 B1 01
				39 01 00 00 00 00 03 F0 A5 A5];
			mi,mdss-dsi-crc-off-command-state = "dsi_hs_mode";

			mi,mdss-dsi-local-hbm-normal-white-1000nit-command = [
					/* Local HBM setting*/
					39 00 00 00 00 00 03 F0 5A 5A
					39 00 00 00 00 00 03 FC 5A 5A
					15 00 00 00 00 00 02 53 30
					39 00 00 00 00 00 03 51 00 00
					15 00 00 00 00 00 02 60 08
					15 00 00 00 00 00 02 F7 07
					15 00 00 00 00 00 02 B0 43
					39 00 00 00 00 00 10 D5
					02 00 00 00 00 24 49 2E
					35 CA 46 2D 09 BA 84
					39 00 00 00 00 00 02 B0 E8
					39 00 00 00 00 00 03 BB 0F FF
					39 00 00 00 00 00 02 B0 60
					39 00 00 00 00 00 10 B9
					0A 9B 0E 1B 85 0A 9B 0E
					10 7A 0A 9B 0E 10 7A
					39 00 00 00 00 00 02 B0 0E
					39 00 00 00 00 00 02 E7 02
					39 00 00 00 00 00 02 B0 36
					39 00 00 00 00 00 06 BA 00 14 00 00 18
					39 00 00 00 00 00 02 B0 6F
					39 00 00 00 00 00 13 B9
					00 40 14 02 80 52 0A 41
					48 1C 27 FF FF FF FF FF
					FF FF
					39 00 00 00 00 00 02 B0 CC
					39 00 00 00 00 00 02 D6 00
					39 00 00 00 00 00 02 B0 81
					39 00 00 00 00 00 37 B9
					16 62 14 2D 83 F2 55 47
					3A 80 08 00 80 08 00 80
					08 00 16 62 14 2D 83 F2
					55 47 3A 80 08 00 80 08
					00 80 08 00 16 62 14 2D
					83 F2 55 47 3A 80 08 00
					80 08 00 80 08 00
					39 00 00 00 00 00 02 B0 B7
					39 00 00 00 00 00 37 B9
					16 C2 1C 2D A3 F2 54 67
					36 80 08 00 80 08 00 80
					08 00 16 C2 1C 2D A3 F2
					54 67 36 80 08 00 80 08
					00 80 08 00 16 C2 1C 2D
					A3 F2 54 67 36 80 08 00
					80 08 00 80 08 00
					15 00 00 00 00 00 02 F7 07
					39 00 00 00 00 00 03 F0 A5 A5
					39 01 00 00 19 00 03 FC A5 A5
			];
			mi,mdss-dsi-local-hbm-normal-white-1000nit-command-state = "dsi_lp_mode";

			mi,mdss-dsi-local-hbm-hlpm-white-1000nit-command = [
					/* nolp*/
					39 00 00 00 00 00 03 F0 5A 5A
					39 00 00 00 00 00 03 FC 5A 5A
					15 00 00 00 00 00 02 60 08
					15 00 00 00 00 00 02 B0 55
					15 00 00 00 00 00 02 D1 0E
					15 00 00 00 00 00 02 53 29
					15 00 00 00 00 00 02 F7 07
					39 00 00 00 00 00 03 FC A5 A5
					39 01 00 00 21 00 03 F0 A5 A5
					/* Local HBM setting*/
					39 00 00 00 00 00 03 F0 5A 5A
					39 00 00 00 00 00 03 FC 5A 5A
					15 00 00 00 00 00 02 53 30
					15 00 00 00 00 00 02 60 08
					15 00 00 00 00 00 02 F7 07
					15 00 00 00 00 00 02 B0 43
					39 00 00 00 00 00 10 D5
					02 00 00 00 00 24 49 2E
					35 CA 46 2D 09 BA 84
					39 00 00 00 00 00 02 B0 E8
					39 00 00 00 00 00 03 BB 0F FF
					39 00 00 00 00 00 02 B0 60
					39 00 00 00 00 00 10 B9
					0A 9B 0E 1B 85 0A 9B 0E
					10 7A 0A 9B 0E 10 7A
					39 00 00 00 00 00 02 B0 0E
					39 00 00 00 00 00 02 E7 02
					39 00 00 00 00 00 02 B0 36
					39 00 00 00 00 00 06 BA 00 14 00 00 18
					39 00 00 00 00 00 02 B0 6F
					39 00 00 00 00 00 13 B9
					00 40 14 02 80 52 0A 41
					48 1C 27 FF FF FF FF FF
					FF FF
					39 00 00 00 00 00 02 B0 CC
					39 00 00 00 00 00 02 D6 00
					39 00 00 00 00 00 02 B0 81
					39 00 00 00 00 00 37 B9
					16 62 14 2D 83 F2 55 47
					3A 80 08 00 80 08 00 80
					08 00 16 62 14 2D 83 F2
					55 47 3A 80 08 00 80 08
					00 80 08 00 16 62 14 2D
					83 F2 55 47 3A 80 08 00
					80 08 00 80 08 00
					39 00 00 00 00 00 02 B0 B7
					39 00 00 00 00 00 37 B9
					16 C2 1C 2D A3 F2 54 67
					36 80 08 00 80 08 00 80
					08 00 16 C2 1C 2D A3 F2
					54 67 36 80 08 00 80 08
					00 80 08 00 16 C2 1C 2D
					A3 F2 54 67 36 80 08 00
					80 08 00 80 08 00
					15 00 00 00 00 00 02 F7 07
					39 00 00 00 00 00 03 F0 A5 A5
					39 01 00 00 22 00 03 FC A5 A5
			];
			mi,mdss-dsi-local-hbm-hlpm-white-1000nit-command-state = "dsi_lp_mode";

			mi,mdss-dsi-local-hbm-normal-white-750nit-command = [
					/* Local HBM setting*/
					39 01 00 00 00 00 03 F0 5A 5A
					39 01 00 00 00 00 03 FC 5A 5A
					15 01 00 00 00 00 02 53 30
					15 01 00 00 00 00 02 60 08
					15 01 00 00 00 00 02 F7 07
					15 01 00 00 00 00 02 B0 43
					39 01 00 00 00 00 10 D5
					02 00 00 00 00 24 49 2E
					35 CA 46 2D 09 BA 84
					39 01 00 00 00 00 02 B0 E8
					39 01 00 00 00 00 03 BB 0F FF
					39 01 00 00 00 00 02 B0 60
					39 01 00 00 00 00 10 B9
					09 8A 6E A4 CA 09 8A 6E
					A0 CA 09 8A 10 44 6A
					39 01 00 00 00 00 02 B0 0E
					39 01 00 00 00 00 02 E7 02
					39 01 00 00 00 00 02 B0 36
					39 01 00 00 00 00 06 BA 00 14 00 00 18
					39 01 00 00 00 00 02 B0 6F
					39 01 00 00 00 00 13 B9
					00 40 14 02 80 52 0A 41
					48 1C 27 FF FF FF FF FF
					FF FF
					39 01 00 00 00 00 02 B0 CC
					39 01 00 00 00 00 02 D6 00
					39 01 00 00 00 00 02 B0 81
					39 01 00 00 00 00 37 B9
					16 62 14 2D 83 F2 55 47
					3A 80 08 00 80 08 00 80
					08 00 16 62 14 2D 83 F2
					55 47 3A 80 08 00 80 08
					00 80 08 00 16 62 14 2D
					83 F2 55 47 3A 80 08 00
					80 08 00 80 08 00
					39 01 00 00 00 00 02 B0 B7
					39 01 00 00 00 00 37 B9
					16 C2 1C 2D A3 F2 54 67
					36 80 08 00 80 08 00 80
					08 00 16 C2 1C 2D A3 F2
					54 67 36 80 08 00 80 08
					00 80 08 00 16 C2 1C 2D
					A3 F2 54 67 36 80 08 00
					80 08 00 80 08 00
					15 01 00 00 00 00 02 F7 07
					39 01 00 00 00 00 03 F0 A5 A5
					39 01 00 00 00 00 03 FC A5 A5
			];
			mi,mdss-dsi-local-hbm-normal-white-750nit-command-state = "dsi_lp_mode";

			mi,mdss-dsi-local-hbm-normal-white-500nit-command = [
					/* Local HBM setting*/
					39 01 00 00 00 00 03 F0 5A 5A
					39 01 00 00 00 00 03 FC 5A 5A
					15 01 00 00 00 00 02 53 30
					15 01 00 00 00 00 02 60 08
					15 01 00 00 00 00 02 F7 07
					15 01 00 00 00 00 02 B0 43
					39 01 00 00 00 00 10 D5
					02 00 00 00 00 24 49 2E
					35 CA 46 2D 09 BA 84
					39 01 00 00 00 00 02 B0 E8
					39 01 00 00 00 00 03 BB 0F FF
					39 01 00 00 00 00 02 B0 60
					39 01 00 00 00 00 10 B9
					08 79 DE FF FA 08 79 DE
					FF FA 08 79 86 AF 9A
					39 01 00 00 00 00 02 B0 0E
					39 01 00 00 00 00 02 E7 02
					39 01 00 00 00 00 02 B0 36
					39 01 00 00 00 00 06 BA 00 14 00 00 18
					39 01 00 00 00 00 02 B0 6F
					39 01 00 00 00 00 13 B9
					00 40 14 02 80 52 0A 41
					48 1C 27 FF FF FF FF FF
					FF FF
					39 01 00 00 00 00 02 B0 CC
					39 01 00 00 00 00 02 D6 00
					39 01 00 00 00 00 02 B0 81
					39 01 00 00 00 00 37 B9
					16 62 14 2D 83 F2 55 47
					3A 80 08 00 80 08 00 80
					08 00 16 62 14 2D 83 F2
					55 47 3A 80 08 00 80 08
					00 80 08 00 16 62 14 2D
					83 F2 55 47 3A 80 08 00
					80 08 00 80 08 00
					39 01 00 00 00 00 02 B0 B7
					39 01 00 00 00 00 37 B9
					16 C2 1C 2D A3 F2 54 67
					36 80 08 00 80 08 00 80
					08 00 16 C2 1C 2D A3 F2
					54 67 36 80 08 00 80 08
					00 80 08 00 16 C2 1C 2D
					A3 F2 54 67 36 80 08 00
					80 08 00 80 08 00
					15 01 00 00 00 00 02 F7 07
					39 01 00 00 00 00 03 F0 A5 A5
					39 01 00 00 00 00 03 FC A5 A5
			];
			mi,mdss-dsi-local-hbm-normal-white-500nit-command-state = "dsi_lp_mode";

			mi,mdss-dsi-local-hbm-normal-white-110nit-command = [
					/* Local HBM setting*/
					39 00 00 00 00 00 03 F0 5A 5A
					39 00 00 00 00 00 03 FC 5A 5A
					15 00 00 00 00 00 02 53 30
					15 00 00 00 00 00 02 60 08
					15 00 00 00 00 00 02 F7 07
					15 00 00 00 00 00 02 B0 43
					39 00 00 00 00 00 10 D5
					02 00 00 00 00 24 49 2E
					35 CA 46 2D 09 BA 84
					39 00 00 00 00 00 02 B0 E8
					39 00 00 00 00 00 03 BB 0F FF
					39 00 00 00 00 00 02 B0 60
					39 00 00 00 00 00 10 B9
					07 68 10 60 00 07 68 10
					60 00 06 67 E8 3B BF
					39 00 00 00 00 00 02 B0 0E
					39 00 00 00 00 00 02 E7 02
					39 00 00 00 00 00 02 B0 36
					39 00 00 00 00 00 06 BA 00 14 00 00 18
					39 00 00 00 00 00 02 B0 6F
					39 00 00 00 00 00 13 B9
					00 40 14 02 80 52 0A 41
					48 1C 27 FF FF FF FF FF
					FF FF
					39 00 00 00 00 00 02 B0 CC
					39 00 00 00 00 00 02 D6 00
					39 00 00 00 00 00 02 B0 81
					39 00 00 00 00 00 37 B9
					16 62 14 2D 83 F2 55 47
					3A 80 08 00 80 08 00 80
					08 00 16 62 14 2D 83 F2
					55 47 3A 80 08 00 80 08
					00 80 08 00 16 62 14 2D
					83 F2 55 47 3A 80 08 00
					80 08 00 80 08 00
					39 00 00 00 00 00 02 B0 B7
					39 00 00 00 00 00 37 B9
					16 C2 1C 2D A3 F2 54 67
					36 80 08 00 80 08 00 80
					08 00 16 C2 1C 2D A3 F2
					54 67 36 80 08 00 80 08
					00 80 08 00 16 C2 1C 2D
					A3 F2 54 67 36 80 08 00
					80 08 00 80 08 00
					15 00 00 00 00 00 02 F7 07
					39 00 00 00 00 00 03 F0 A5 A5
					39 01 00 00 19 00 03 FC A5 A5
			];
			mi,mdss-dsi-local-hbm-normal-white-110nit-command-state = "dsi_lp_mode";

			mi,mdss-dsi-local-hbm-hlpm-white-110nit-command = [
					/* nolp*/
					39 00 00 00 00 00 03 F0 5A 5A
					39 00 00 00 00 00 03 FC 5A 5A
					15 00 00 00 00 00 02 60 08
					15 00 00 00 00 00 02 B0 55
					15 00 00 00 00 00 02 D1 0E
					15 00 00 00 00 00 02 53 29
					15 00 00 00 00 00 02 F7 07
					39 00 00 00 00 00 03 FC A5 A5
					39 01 00 00 21 00 03 F0 A5 A5
					/* Local HBM setting*/
					39 00 00 00 00 00 03 F0 5A 5A
					39 00 00 00 00 00 03 FC 5A 5A
					15 00 00 00 00 00 02 53 30
					15 00 00 00 00 00 02 60 08
					15 00 00 00 00 00 02 F7 07
					15 00 00 00 00 00 02 B0 43
					39 00 00 00 00 00 10 D5
					02 00 00 00 00 24 49 2E
					35 CA 46 2D 09 BA 84
					39 00 00 00 00 00 02 B0 E8
					39 00 00 00 00 00 03 BB 0F FF
					39 00 00 00 00 00 02 B0 60
					39 00 00 00 00 00 10 B9
					07 68 10 60 00 07 68 10
					60 00 06 67 E8 3B BF
					39 00 00 00 00 00 02 B0 0E
					39 00 00 00 00 00 02 E7 02
					39 00 00 00 00 00 02 B0 36
					39 00 00 00 00 00 06 BA 00 14 00 00 18
					39 00 00 00 00 00 02 B0 6F
					39 00 00 00 00 00 13 B9
					00 40 14 02 80 52 0A 41
					48 1C 27 FF FF FF FF FF
					FF FF
					39 00 00 00 00 00 02 B0 CC
					39 00 00 00 00 00 02 D6 00
					39 00 00 00 00 00 02 B0 81
					39 00 00 00 00 00 37 B9
					16 62 14 2D 83 F2 55 47
					3A 80 08 00 80 08 00 80
					08 00 16 62 14 2D 83 F2
					55 47 3A 80 08 00 80 08
					00 80 08 00 16 62 14 2D
					83 F2 55 47 3A 80 08 00
					80 08 00 80 08 00
					39 00 00 00 00 00 02 B0 B7
					39 00 00 00 00 00 37 B9
					16 C2 1C 2D A3 F2 54 67
					36 80 08 00 80 08 00 80
					08 00 16 C2 1C 2D A3 F2
					54 67 36 80 08 00 80 08
					00 80 08 00 16 C2 1C 2D
					A3 F2 54 67 36 80 08 00
					80 08 00 80 08 00
					15 00 00 00 00 00 02 F7 07
					39 00 00 00 00 00 03 F0 A5 A5
					39 01 00 00 22 00 03 FC A5 A5
			];
			mi,mdss-dsi-local-hbm-hlpm-white-110nit-command-state = "dsi_lp_mode";

			mi,mdss-dsi-local-hbm-normal-green-500nit-command = [
					/* Local HBM setting*/
					39 01 00 00 00 00 03 F0 5A 5A
					39 01 00 00 00 00 03 FC 5A 5A
					15 01 00 00 00 00 02 53 30
					15 01 00 00 00 00 02 60 08
					15 01 00 00 00 00 02 F7 07
					15 01 00 00 00 00 02 B0 43
					39 01 00 00 00 00 10 D5
					02 00 00 00 00 24 49 2E
					35 CA 46 2D 09 BA 84
					39 01 00 00 00 00 02 B0 E8
					39 01 00 00 00 00 03 BB 0F FF
					39 01 00 00 00 00 02 B0 60
					39 01 00 00 00 00 10 B9
					00 80 00 85 00 00 80 00
					85 00 00 80 00 25 00
					39 01 00 00 00 00 02 B0 0E
					39 01 00 00 00 00 02 E7 02
					39 01 00 00 00 00 02 B0 36
					39 01 00 00 00 00 06 BA 00 14 00 00 18
					39 01 00 00 00 00 02 B0 6F
					39 01 00 00 00 00 13 B9
					00 40 14 02 80 52 0A 41
					48 1C 27 FF FF FF FF FF
					FF FF
					39 01 00 00 00 00 02 B0 CC
					39 01 00 00 00 00 02 D6 00
					39 01 00 00 00 00 02 B0 81
					39 01 00 00 00 00 37 B9
					16 62 14 2D 83 F2 55 47
					3A 80 08 00 80 08 00 80
					08 00 16 62 14 2D 83 F2
					55 47 3A 80 08 00 80 08
					00 80 08 00 16 62 14 2D
					83 F2 55 47 3A 80 08 00
					80 08 00 80 08 00
					39 01 00 00 00 00 02 B0 B7
					39 01 00 00 00 00 37 B9
					16 C2 1C 2D A3 F2 54 67
					36 80 08 00 80 08 00 80
					08 00 16 C2 1C 2D A3 F2
					54 67 36 80 08 00 80 08
					00 80 08 00 16 C2 1C 2D
					A3 F2 54 67 36 80 08 00
					80 08 00 80 08 00
					15 01 00 00 00 00 02 F7 07
					39 01 00 00 00 00 03 F0 A5 A5
					39 01 00 00 00 00 03 FC A5 A5
			];
			mi,mdss-dsi-local-hbm-normal-green-500nit-command-state = "dsi_lp_mode";

			mi,mdss-dsi-local-hbm-off-to-normal-command = [
					/* Local HBM setting*/
					39 00 00 00 00 00 03 F0 5A 5A
					15 00 00 00 00 00 02 53 20
					39 01 00 00 00 00 03 F0 A5 A5
			];
			mi,mdss-dsi-local-hbm-off-to-normal-command-state = "dsi_lp_mode";

			mi,mdss-dsi-local-hbm-off-to-hbm-command = [
					/* Local HBM setting*/
					39 00 00 00 00 00 03 F0 5A 5A
					15 00 00 00 00 00 02 53 E8
					39 00 00 00 00 00 03 51 00 00
					15 00 00 00 00 00 02 F7 07
					39 01 00 00 00 00 03 F0 A5 A5
			];
			mi,mdss-dsi-local-hbm-off-to-hbm-command-state = "dsi_lp_mode";

			mi,mdss-dsi-local-hbm-off-to-hlpm-command = [
					/* Local HBM setting*/
					39 00 00 00 00 00 03 F0 5A 5A
					15 00 00 00 00 00 02 53 24
					15 00 00 00 00 00 02 F7 07
					39 01 00 00 00 00 03 F0 A5 A5
			];
			mi,mdss-dsi-local-hbm-off-to-hlpm-command-state = "dsi_lp_mode";

			mi,mdss-dsi-local-hbm-off-to-llpm-command = [
					/* Local HBM setting*/
					39 00 00 00 00 00 03 F0 5A 5A
					15 00 00 00 00 00 02 53 25
					15 00 00 00 00 00 02 F7 07
					39 01 00 00 00 00 03 F0 A5 A5
			];
			mi,mdss-dsi-local-hbm-off-to-llpm-command-state = "dsi_lp_mode";

			mi,mdss-dsi-spr-1d-rendering-command = [
					39 00 00 00 00 00 03 F0 5A 5A
					39 00 00 00 00 00 08 B3 00 00 D8 D8 C0 C0 71         /* 1D Rendering */
					39 01 00 00 00 00 03 F0 A5 A5
			];
			mi,mdss-dsi-spr-1d-rendering-command-state = "dsi_lp_mode";

			mi,mdss-dsi-spr-2d-rendering-command = [
					39 00 00 00 00 00 03 F0 5A 5A
					39 00 00 00 00 00 08 B3 00 00 D8 D8 FF FF 40         /* 2D Rendering */
					39 01 00 00 00 00 03 F0 A5 A5
			];
			mi,mdss-dsi-spr-2d-rendering-command-state = "dsi_lp_mode";

			mi,mdss-dsi-color-invert-on-command = [05 01 00 00 00 00 01 21];
			mi,mdss-dsi-color-invert-on-command-state = "dsi_lp_mode";

			mi,mdss-dsi-color-invert-off-command = [05 01 00 00 00 00 01 20];
			mi,mdss-dsi-color-invert-off-command-state = "dsi_lp_mode";
		};

		timing@1{
			mi,mdss-dsi-dimmingon-command = [15 01 00 00 00 00 02 53 28];
			mi,mdss-dsi-dimmingon-command-state = "dsi_hs_mode";
			mi,mdss-dsi-dimmingoff-command = [15 01 00 00 00 00 02 53 20];
			mi,mdss-dsi-dimmingoff-command-state = "dsi_hs_mode";

			mi,mdss-dsi-hbm-on-command = [
				39 01 00 00 00 00 03 F0 5A 5A
				15 00 00 00 00 00 02 53 E8
				39 00 00 00 00 00 03 51 00 00
				15 01 00 00 00 00 02 F7 07
				39 01 00 00 00 00 03 F0 A5 A5
			];
			mi,mdss-dsi-hbm-off-command = [
				39 01 00 00 00 00 03 F0 5A 5A
				15 00 00 00 00 00 02 53 28
				39 00 00 00 00 00 03 51 07 FF
				15 01 00 00 00 00 02 F7 07
				39 01 00 00 00 00 03 F0 A5 A5
			];
			mi,mdss-dsi-hbm-on-command-state = "dsi_lp_mode";
			mi,mdss-dsi-hbm-off-command-state = "dsi_lp_mode";

			mi,mdss-dsi-hbm-fod-on-command = [
				39 01 00 00 00 00 03 F0 5A 5A
				/* HBM On */
				15 00 00 00 00 00 02 53 E0
				39 00 00 00 00 00 03 51 07 FF
				15 01 00 00 00 00 02 F7 07
				39 01 00 00 00 00 03 F0 A5 A5
			];
			mi,mdss-dsi-hbm-fod-off-command = [
				39 01 00 00 00 00 03 F0 5A 5A
				/* HBM off*/
				15 00 00 00 00 00 02 53 20
				39 00 00 00 00 00 03 51 07 FF
				15 01 00 00 00 00 02 F7 07
				39 01 00 00 00 00 03 F0 A5 A5
			];
			mi,mdss-dsi-hbm-fod-on-command-state = "dsi_lp_mode";
			mi,mdss-dsi-hbm-fod-off-command-state = "dsi_lp_mode";

			mi,mdss-dsi-doze-hbm-command = [
				39 01 00 00 00 00 03 F0 5A 5A
				15 00 00 00 00 00 02 53 24
				15 01 00 00 00 00 02 F7 07
				39 01 00 00 00 00 03 F0 A5 A5
			];

			mi,mdss-dsi-doze-lbm-command = [
				39 01 00 00 00 00 03 F0 5A 5A
				15 00 00 00 00 00 02 53 25
				15 01 00 00 00 00 02 F7 07
				39 01 00 00 00 00 03 F0 A5 A5
			];
			mi,mdss-dsi-doze-hbm-command-state = "dsi_lp_mode";
			mi,mdss-dsi-doze-lbm-command-state = "dsi_lp_mode";

			mi,mdss-dsi-doze-hbm-nolp-command = [
				39 00 00 00 00 00 03 F0 5A 5A
				39 00 00 00 00 00 03 FC 5A 5A
				15 00 00 00 00 00 02 60 00
				15 00 00 00 00 00 02 B0 55
				15 00 00 00 00 00 02 D1 0E
				15 00 00 00 00 00 02 53 28
				15 00 00 00 00 00 02 F7 07
				39 00 00 00 00 00 03 FC A5 A5
				39 01 00 00 4C 00 03 F0 A5 A5
			];
			mi,mdss-dsi-doze-hbm-nolp-command-state = "dsi_lp_mode";
			mi,mdss-dsi-doze-lbm-nolp-command = [
				39 00 00 00 00 00 03 F0 5A 5A
				39 00 00 00 00 00 03 FC 5A 5A
				15 00 00 00 00 00 02 60 00
				15 00 00 00 00 00 02 B0 55
				15 00 00 00 00 00 02 D1 0E
				15 00 00 00 00 00 02 53 29
				15 00 00 00 00 00 02 F7 07
				39 00 00 00 00 00 03 FC A5 A5
				39 01 00 00 4C 00 03 F0 A5 A5
			];
			mi,mdss-dsi-doze-lbm-nolp-command-state = "dsi_lp_mode";

			mi,mdss-dsi-flat-mode-on-command = [
				39 01 00 00 00 00 03 F0 5A 5A
				39 00 00 00 00 00 29 C6
				37 21 8D FF 55 86 00 B0
				0E FF FF 0E FF 80 91 13
				0F 0F 0F 3D 3D 3D 51 51
				51 60 60 60 66 66 66 A4
				E4 A4 08 00 80 00 00 22
				15 01 00 00 00 00 02 F7 07
				39 01 00 00 09 00 03 F0 A5 A5

			];
			mi,mdss-dsi-nature-flat-mode-on-command = [
				39 01 00 00 00 00 03 F0 5A 5A
				39 01 00 00 00 00 29 C6 37 21 E1 FF
				67 86 00 B0 0E FF FF 0E FF 80 91 13
				0E 0F 0E 3B 3D 38 4F 51 4B 5E 60 59
				63 66 5E A4 E4 A4 08 00 80 00 00 22
				39 01 00 00 00 00 02 B0 CD
				39 01 00 00 00 00 0F D3 E2 06 06 06
				92 2C 6A 80 5F 4C 40 33 FF 90
				39 01 00 00 00 00 02 F7 07
			];
			mi,mdss-dsi-flat-mode-off-command = [
				39 01 00 00 00 00 03 F0 5A 5A
				39 00 00 00 00 00 29 C6
				37 01 8D FF 55 86 00 B0
				0E FF FF 0E FF 80 91 13
				0F 0F 0F 3D 3D 3D 51 51
				51 60 60 60 66 66 66 A4
				E4 A4 08 00 80 00 00 22
				15 01 00 00 00 00 02 F7 07
				39 01 00 00 09 00 03 F0 A5 A5

			];
			mi,mdss-dsi-nature-flat-mode-off-command = [
				39 01 00 00 00 00 03 F0 5A 5A
				39 01 00 00 00 00 29 C6 37 01 E1 FF
				67 86 00 B0 0E FF FF 0E FF 80 91 13
				0E 0F 0E 3B 3D 38 4F 51 4B 5E 60 59
				63 66 5E A4 E4 A4 08 00 80 00 00 22
				39 01 00 00 00 00 02 B0 CD
				39 01 00 00 00 00 02 D3 00
				39 01 00 00 00 00 02 F7 07
			];
			mi,mdss-dsi-flat-mode-on-command-state = "dsi_lp_mode";
			mi,mdss-dsi-nature-flat-mode-on-command-state = "dsi_lp_mode";
			mi,mdss-dsi-flat-mode-off-command-state = "dsi_lp_mode";
			mi,mdss-dsi-nature-flat-mode-off-command-state = "dsi_lp_mode";
			mi,mdss-dsi-crc-off-command = [
				/* CRC Disable (Normal mode) */
				39 01 00 00 00 00 02 80 00
				39 00 00 00 00 00 03 F0 5A 5A
				/* CRC Bypass */
				39 00 00 00 00 00 02 B1 01
				39 01 00 00 00 00 03 F0 A5 A5];
			mi,mdss-dsi-crc-off-command-state = "dsi_hs_mode";

			mi,mdss-dsi-local-hbm-normal-white-1000nit-command = [
					/* Local HBM setting*/
					39 00 00 00 00 00 03 F0 5A 5A
					39 00 00 00 00 00 03 FC 5A 5A
					15 00 00 00 00 00 02 53 30
					39 00 00 00 00 00 03 51 00 00
					15 00 00 00 00 00 02 60 00
					15 00 00 00 00 00 02 F7 07
					15 00 00 00 00 00 02 B0 43
					39 00 00 00 00 00 10 D5
					02 00 00 00 00 24 49 2E
					35 CA 46 2D 09 BA 84
					39 00 00 00 00 00 02 B0 E8
					39 00 00 00 00 00 03 BB 0F FF
					39 00 00 00 00 00 02 B0 60
					39 00 00 00 00 00 10 B9
					0A 9B 0E 1B 85 0A 9B 0E
					10 7A 0A 9B 0E 10 7A
					39 00 00 00 00 00 02 B0 0E
					39 00 00 00 00 00 02 E7 02
					39 00 00 00 00 00 02 B0 36
					39 00 00 00 00 00 06 BA 00 14 00 00 18
					39 00 00 00 00 00 02 B0 6F
					39 00 00 00 00 00 13 B9
					00 40 14 02 80 52 0A 41
					48 1C 27 FF FF FF FF FF
					FF FF
					39 00 00 00 00 00 02 B0 CC
					39 00 00 00 00 00 02 D6 00
					39 00 00 00 00 00 02 B0 81
					39 00 00 00 00 00 37 B9
					16 62 14 2D 83 F2 55 47
					3A 80 08 00 80 08 00 80
					08 00 16 62 14 2D 83 F2
					55 47 3A 80 08 00 80 08
					00 80 08 00 16 62 14 2D
					83 F2 55 47 3A 80 08 00
					80 08 00 80 08 00
					39 00 00 00 00 00 02 B0 B7
					39 00 00 00 00 00 37 B9
					16 C2 1C 2D A3 F2 54 67
					36 80 08 00 80 08 00 80
					08 00 16 C2 1C 2D A3 F2
					54 67 36 80 08 00 80 08
					00 80 08 00 16 C2 1C 2D
					A3 F2 54 67 36 80 08 00
					80 08 00 80 08 00
					15 00 00 00 00 00 02 F7 07
					39 00 00 00 00 00 03 F0 A5 A5
					39 01 00 00 32 00 03 FC A5 A5
			];
			mi,mdss-dsi-local-hbm-normal-white-1000nit-command-state = "dsi_lp_mode";

			mi,mdss-dsi-local-hbm-hlpm-white-1000nit-command = [
					/* 60hz lbm nolp */
					39 00 00 00 00 00 03 F0 5A 5A
					39 00 00 00 00 00 03 FC 5A 5A
					15 00 00 00 00 00 02 60 00
					15 00 00 00 00 00 02 B0 55
					15 00 00 00 00 00 02 D1 0E
					15 00 00 00 00 00 02 53 29
					15 00 00 00 00 00 02 F7 07
					39 00 00 00 00 00 03 FC A5 A5
					39 01 00 00 21 00 03 F0 A5 A5
					/* Local HBM setting*/
					39 00 00 00 00 00 03 F0 5A 5A
					39 00 00 00 00 00 03 FC 5A 5A
					15 00 00 00 00 00 02 53 30
					15 00 00 00 00 00 02 60 00
					15 00 00 00 00 00 02 F7 07
					15 00 00 00 00 00 02 B0 43
					39 00 00 00 00 00 10 D5
					02 00 00 00 00 24 49 2E
					35 CA 46 2D 09 BA 84
					39 00 00 00 00 00 02 B0 E8
					39 00 00 00 00 00 03 BB 0F FF
					39 00 00 00 00 00 02 B0 60
					39 00 00 00 00 00 10 B9
					0A 9B 0E 1B 85 0A 9B 0E
					10 7A 0A 9B 0E 10 7A
					39 00 00 00 00 00 02 B0 0E
					39 00 00 00 00 00 02 E7 02
					39 00 00 00 00 00 02 B0 36
					39 00 00 00 00 00 06 BA 00 14 00 00 18
					39 00 00 00 00 00 02 B0 6F
					39 00 00 00 00 00 13 B9
					00 40 14 02 80 52 0A 41
					48 1C 27 FF FF FF FF FF
					FF FF
					39 00 00 00 00 00 02 B0 CC
					39 00 00 00 00 00 02 D6 00
					39 00 00 00 00 00 02 B0 81
					39 00 00 00 00 00 37 B9
					16 62 14 2D 83 F2 55 47
					3A 80 08 00 80 08 00 80
					08 00 16 62 14 2D 83 F2
					55 47 3A 80 08 00 80 08
					00 80 08 00 16 62 14 2D
					83 F2 55 47 3A 80 08 00
					80 08 00 80 08 00
					39 00 00 00 00 00 02 B0 B7
					39 00 00 00 00 00 37 B9
					16 C2 1C 2D A3 F2 54 67
					36 80 08 00 80 08 00 80
					08 00 16 C2 1C 2D A3 F2
					54 67 36 80 08 00 80 08
					00 80 08 00 16 C2 1C 2D
					A3 F2 54 67 36 80 08 00
					80 08 00 80 08 00
					15 00 00 00 00 00 02 F7 07
					39 00 00 00 00 00 03 F0 A5 A5
					39 01 00 00 41 00 03 FC A5 A5
			];
			mi,mdss-dsi-local-hbm-hlpm-white-1000nit-command-state = "dsi_lp_mode";

			mi,mdss-dsi-local-hbm-normal-white-750nit-command = [
					/* Local HBM setting*/
					39 01 00 00 00 00 03 F0 5A 5A
					39 01 00 00 00 00 03 FC 5A 5A
					15 01 00 00 00 00 02 53 30
					15 01 00 00 00 00 02 60 00
					15 01 00 00 00 00 02 F7 07
					15 01 00 00 00 00 02 B0 43
					39 01 00 00 00 00 10 D5
					02 00 00 00 00 24 49 2E
					35 CA 46 2D 09 BA 84
					39 01 00 00 00 00 02 B0 E8
					39 01 00 00 00 00 03 BB 0F FF
					39 01 00 00 00 00 02 B0 60
					39 01 00 00 00 00 10 B9
					09 8A 6E A4 CA 09 8A 6E
					A0 CA 09 8A 10 44 6A
					39 01 00 00 00 00 02 B0 0E
					39 01 00 00 00 00 02 E7 02
					39 01 00 00 00 00 02 B0 36
					39 01 00 00 00 00 06 BA 00 14 00 00 18
					39 01 00 00 00 00 02 B0 6F
					39 01 00 00 00 00 13 B9
					00 40 14 02 80 52 0A 41
					48 1C 27 FF FF FF FF FF
					FF FF
					39 01 00 00 00 00 02 B0 CC
					39 01 00 00 00 00 02 D6 00
					39 01 00 00 00 00 02 B0 81
					39 01 00 00 00 00 37 B9
					16 62 14 2D 83 F2 55 47
					3A 80 08 00 80 08 00 80
					08 00 16 62 14 2D 83 F2
					55 47 3A 80 08 00 80 08
					00 80 08 00 16 62 14 2D
					83 F2 55 47 3A 80 08 00
					80 08 00 80 08 00
					39 01 00 00 00 00 02 B0 B7
					39 01 00 00 00 00 37 B9
					16 C2 1C 2D A3 F2 54 67
					36 80 08 00 80 08 00 80
					08 00 16 C2 1C 2D A3 F2
					54 67 36 80 08 00 80 08
					00 80 08 00 16 C2 1C 2D
					A3 F2 54 67 36 80 08 00
					80 08 00 80 08 00
					15 01 00 00 00 00 02 F7 07
					39 01 00 00 00 00 03 F0 A5 A5
					39 01 00 00 00 00 03 FC A5 A5
			];
			mi,mdss-dsi-local-hbm-normal-white-750nit-command-state = "dsi_lp_mode";

			mi,mdss-dsi-local-hbm-normal-white-500nit-command = [
					/* Local HBM setting*/
					39 01 00 00 00 00 03 F0 5A 5A
					39 01 00 00 00 00 03 FC 5A 5A
					15 01 00 00 00 00 02 53 30
					15 01 00 00 00 00 02 60 00
					15 01 00 00 00 00 02 F7 07
					15 01 00 00 00 00 02 B0 43
					39 01 00 00 00 00 10 D5
					02 00 00 00 00 24 49 2E
					35 CA 46 2D 09 BA 84
					39 01 00 00 00 00 02 B0 E8
					39 01 00 00 00 00 03 BB 0F FF
					39 01 00 00 00 00 02 B0 60
					39 01 00 00 00 00 10 B9
					08 79 DE FF FA 08 79 DE
					FF FA 08 79 86 AF 9A
					39 01 00 00 00 00 02 B0 0E
					39 01 00 00 00 00 02 E7 02
					39 01 00 00 00 00 02 B0 36
					39 01 00 00 00 00 06 BA 00 14 00 00 18
					39 01 00 00 00 00 02 B0 6F
					39 01 00 00 00 00 13 B9
					00 40 14 02 80 52 0A 41
					48 1C 27 FF FF FF FF FF
					FF FF
					39 01 00 00 00 00 02 B0 CC
					39 01 00 00 00 00 02 D6 00
					39 01 00 00 00 00 02 B0 81
					39 01 00 00 00 00 37 B9
					16 62 14 2D 83 F2 55 47
					3A 80 08 00 80 08 00 80
					08 00 16 62 14 2D 83 F2
					55 47 3A 80 08 00 80 08
					00 80 08 00 16 62 14 2D
					83 F2 55 47 3A 80 08 00
					80 08 00 80 08 00
					39 01 00 00 00 00 02 B0 B7
					39 01 00 00 00 00 37 B9
					16 C2 1C 2D A3 F2 54 67
					36 80 08 00 80 08 00 80
					08 00 16 C2 1C 2D A3 F2
					54 67 36 80 08 00 80 08
					00 80 08 00 16 C2 1C 2D
					A3 F2 54 67 36 80 08 00
					80 08 00 80 08 00
					15 01 00 00 00 00 02 F7 07
					39 01 00 00 00 00 03 F0 A5 A5
					39 01 00 00 00 00 03 FC A5 A5
			];
			mi,mdss-dsi-local-hbm-normal-white-500nit-command-state = "dsi_lp_mode";

			mi,mdss-dsi-local-hbm-normal-white-110nit-command = [
					/* Local HBM setting*/
					39 00 00 00 00 00 03 F0 5A 5A
					39 00 00 00 00 00 03 FC 5A 5A
					15 00 00 00 00 00 02 53 30
					15 00 00 00 00 00 02 60 00
					15 00 00 00 00 00 02 F7 07
					15 00 00 00 00 00 02 B0 43
					39 00 00 00 00 00 10 D5
					02 00 00 00 00 24 49 2E
					35 CA 46 2D 09 BA 84
					39 00 00 00 00 00 02 B0 E8
					39 00 00 00 00 00 03 BB 0F FF
					39 00 00 00 00 00 02 B0 60
					39 00 00 00 00 00 10 B9
					07 68 10 60 00 07 68 10
					60 00 06 67 E8 3B BF
					39 00 00 00 00 00 02 B0 0E
					39 00 00 00 00 00 02 E7 02
					39 00 00 00 00 00 02 B0 36
					39 00 00 00 00 00 06 BA 00 14 00 00 18
					39 00 00 00 00 00 02 B0 6F
					39 00 00 00 00 00 13 B9
					00 40 14 02 80 52 0A 41
					48 1C 27 FF FF FF FF FF
					FF FF
					39 00 00 00 00 00 02 B0 CC
					39 00 00 00 00 00 02 D6 00
					39 00 00 00 00 00 02 B0 81
					39 00 00 00 00 00 37 B9
					16 62 14 2D 83 F2 55 47
					3A 80 08 00 80 08 00 80
					08 00 16 62 14 2D 83 F2
					55 47 3A 80 08 00 80 08
					00 80 08 00 16 62 14 2D
					83 F2 55 47 3A 80 08 00
					80 08 00 80 08 00
					39 00 00 00 00 00 02 B0 B7
					39 00 00 00 00 00 37 B9
					16 C2 1C 2D A3 F2 54 67
					36 80 08 00 80 08 00 80
					08 00 16 C2 1C 2D A3 F2
					54 67 36 80 08 00 80 08
					00 80 08 00 16 C2 1C 2D
					A3 F2 54 67 36 80 08 00
					80 08 00 80 08 00
					15 00 00 00 00 00 02 F7 07
					39 00 00 00 00 00 03 F0 A5 A5
					39 01 00 00 32 00 03 FC A5 A5
			];
			mi,mdss-dsi-local-hbm-normal-white-110nit-command-state = "dsi_lp_mode";

			mi,mdss-dsi-local-hbm-hlpm-white-110nit-command = [
					/* 60hz lbm nolp */
					39 00 00 00 00 00 03 F0 5A 5A
					39 00 00 00 00 00 03 FC 5A 5A
					15 00 00 00 00 00 02 60 00
					15 00 00 00 00 00 02 B0 55
					15 00 00 00 00 00 02 D1 0E
					15 00 00 00 00 00 02 53 29
					15 00 00 00 00 00 02 F7 07
					39 00 00 00 00 00 03 FC A5 A5
					39 01 00 00 21 00 03 F0 A5 A5
					/* Local HBM setting*/
					39 00 00 00 00 00 03 F0 5A 5A
					39 00 00 00 00 00 03 FC 5A 5A
					15 00 00 00 00 00 02 53 30
					15 00 00 00 00 00 02 60 00
					15 00 00 00 00 00 02 F7 07
					15 00 00 00 00 00 02 B0 43
					39 00 00 00 00 00 10 D5
					02 00 00 00 00 24 49 2E
					35 CA 46 2D 09 BA 84
					39 00 00 00 00 00 02 B0 E8
					39 00 00 00 00 00 03 BB 0F FF
					39 00 00 00 00 00 02 B0 60
					39 00 00 00 00 00 10 B9
					07 68 10 60 00 07 68 10
					60 00 06 67 E8 3B BF
					39 00 00 00 00 00 02 B0 0E
					39 00 00 00 00 00 02 E7 02
					39 00 00 00 00 00 02 B0 36
					39 00 00 00 00 00 06 BA 00 14 00 00 18
					39 00 00 00 00 00 02 B0 6F
					39 00 00 00 00 00 13 B9
					00 40 14 02 80 52 0A 41
					48 1C 27 FF FF FF FF FF
					FF FF
					39 00 00 00 00 00 02 B0 CC
					39 00 00 00 00 00 02 D6 00
					39 00 00 00 00 00 02 B0 81
					39 00 00 00 00 00 37 B9
					16 62 14 2D 83 F2 55 47
					3A 80 08 00 80 08 00 80
					08 00 16 62 14 2D 83 F2
					55 47 3A 80 08 00 80 08
					00 80 08 00 16 62 14 2D
					83 F2 55 47 3A 80 08 00
					80 08 00 80 08 00
					39 00 00 00 00 00 02 B0 B7
					39 00 00 00 00 00 37 B9
					16 C2 1C 2D A3 F2 54 67
					36 80 08 00 80 08 00 80
					08 00 16 C2 1C 2D A3 F2
					54 67 36 80 08 00 80 08
					00 80 08 00 16 C2 1C 2D
					A3 F2 54 67 36 80 08 00
					80 08 00 80 08 00
					15 00 00 00 00 00 02 F7 07
					39 00 00 00 00 00 03 F0 A5 A5
					39 01 00 00 41 00 03 FC A5 A5
			];
			mi,mdss-dsi-local-hbm-hlpm-white-110nit-command-state = "dsi_lp_mode";

			mi,mdss-dsi-local-hbm-normal-green-500nit-command = [
					/* Local HBM setting*/
					39 01 00 00 00 00 03 F0 5A 5A
					39 01 00 00 00 00 03 FC 5A 5A
					15 01 00 00 00 00 02 53 30
					15 01 00 00 00 00 02 60 00
					15 01 00 00 00 00 02 F7 07
					15 01 00 00 00 00 02 B0 43
					39 01 00 00 00 00 10 D5
					02 00 00 00 00 24 49 2E
					35 CA 46 2D 09 BA 84
					39 01 00 00 00 00 02 B0 E8
					39 01 00 00 00 00 03 BB 0F FF
					39 01 00 00 00 00 02 B0 60
					39 01 00 00 00 00 10 B9
					00 80 00 85 00 00 80 00
					85 00 00 80 00 25 00
					39 01 00 00 00 00 02 B0 0E
					39 01 00 00 00 00 02 E7 02
					39 01 00 00 00 00 02 B0 36
					39 01 00 00 00 00 06 BA 00 14 00 00 18
					39 01 00 00 00 00 02 B0 6F
					39 01 00 00 00 00 13 B9
					00 40 14 02 80 52 0A 41
					48 1C 27 FF FF FF FF FF
					FF FF
					39 01 00 00 00 00 02 B0 CC
					39 01 00 00 00 00 02 D6 00
					39 01 00 00 00 00 02 B0 81
					39 01 00 00 00 00 37 B9
					16 62 14 2D 83 F2 55 47
					3A 80 08 00 80 08 00 80
					08 00 16 62 14 2D 83 F2
					55 47 3A 80 08 00 80 08
					00 80 08 00 16 62 14 2D
					83 F2 55 47 3A 80 08 00
					80 08 00 80 08 00
					39 01 00 00 00 00 02 B0 B7
					39 01 00 00 00 00 37 B9
					16 C2 1C 2D A3 F2 54 67
					36 80 08 00 80 08 00 80
					08 00 16 C2 1C 2D A3 F2
					54 67 36 80 08 00 80 08
					00 80 08 00 16 C2 1C 2D
					A3 F2 54 67 36 80 08 00
					80 08 00 80 08 00
					15 01 00 00 00 00 02 F7 07
					39 01 00 00 00 00 03 F0 A5 A5
					39 01 00 00 00 00 03 FC A5 A5
			];
			mi,mdss-dsi-local-hbm-normal-green-500nit-command-state = "dsi_lp_mode";

			mi,mdss-dsi-local-hbm-off-to-normal-command = [
					/* Local HBM setting*/
					39 00 00 00 00 00 03 F0 5A 5A
					15 00 00 00 00 00 02 53 20
					39 01 00 00 00 00 03 F0 A5 A5
			];
			mi,mdss-dsi-local-hbm-off-to-normal-command-state = "dsi_lp_mode";

			mi,mdss-dsi-local-hbm-off-to-hbm-command = [
					/* Local HBM setting*/
					39 00 00 00 00 00 03 F0 5A 5A
					15 00 00 00 00 00 02 53 E8
					39 00 00 00 00 00 03 51 00 00
					15 00 00 00 00 00 02 F7 07
					39 01 00 00 00 00 03 F0 A5 A5
			];
			mi,mdss-dsi-local-hbm-off-to-hbm-command-state = "dsi_lp_mode";

			mi,mdss-dsi-local-hbm-off-to-hlpm-command = [
					/* Local HBM setting*/
					39 00 00 00 00 00 03 F0 5A 5A
					15 00 00 00 00 00 02 53 24
					15 00 00 00 00 00 02 F7 07
					39 01 00 00 00 00 03 F0 A5 A5
			];
			mi,mdss-dsi-local-hbm-off-to-hlpm-command-state = "dsi_lp_mode";

			mi,mdss-dsi-local-hbm-off-to-llpm-command = [
					/* Local HBM setting*/
					39 00 00 00 00 00 03 F0 5A 5A
					15 00 00 00 00 00 02 53 25
					15 00 00 00 00 00 02 F7 07
					39 01 00 00 00 00 03 F0 A5 A5
			];
			mi,mdss-dsi-local-hbm-off-to-llpm-command-state = "dsi_lp_mode";

			mi,mdss-dsi-spr-1d-rendering-command = [
					39 00 00 00 00 00 03 F0 5A 5A
					39 00 00 00 00 00 08 B3 00 00 D8 D8 C0 C0 71         /* 1D Rendering */
					39 01 00 00 00 00 03 F0 A5 A5
			];
			mi,mdss-dsi-spr-1d-rendering-command-state = "dsi_lp_mode";

			mi,mdss-dsi-spr-2d-rendering-command = [
					39 00 00 00 00 00 03 F0 5A 5A
					39 00 00 00 00 00 08 B3 00 00 D8 D8 FF FF 40         /* 2D Rendering */
					39 01 00 00 00 00 03 F0 A5 A5
			];
			mi,mdss-dsi-spr-2d-rendering-command-state = "dsi_lp_mode";

			mi,mdss-dsi-color-invert-on-command = [05 01 00 00 00 00 01 21];
			mi,mdss-dsi-color-invert-on-command-state = "dsi_lp_mode";

			mi,mdss-dsi-color-invert-off-command = [05 01 00 00 00 00 01 20];
			mi,mdss-dsi-color-invert-off-command-state = "dsi_lp_mode";
		};

		timing@2{
			mi,mdss-dsi-dimmingon-command = [15 01 00 00 00 00 02 53 28];
			mi,mdss-dsi-dimmingon-command-state = "dsi_hs_mode";
			mi,mdss-dsi-dimmingoff-command = [15 01 00 00 00 00 02 53 20];
			mi,mdss-dsi-dimmingoff-command-state = "dsi_hs_mode";

			mi,mdss-dsi-hbm-on-command = [
				39 01 00 00 00 00 03 F0 5A 5A
				15 00 00 00 00 00 02 53 E8
				39 00 00 00 00 00 03 51 00 00
				15 01 00 00 00 00 02 F7 07
				39 01 00 00 00 00 03 F0 A5 A5
			];
			mi,mdss-dsi-hbm-off-command = [
				39 01 00 00 00 00 03 F0 5A 5A
				15 00 00 00 00 00 02 53 28
				39 00 00 00 00 00 03 51 07 FF
				15 01 00 00 00 00 02 F7 07
				39 01 00 00 00 00 03 F0 A5 A5
			];
			mi,mdss-dsi-hbm-on-command-state = "dsi_lp_mode";
			mi,mdss-dsi-hbm-off-command-state = "dsi_lp_mode";

			mi,mdss-dsi-hbm-fod-on-command = [
				39 01 00 00 00 00 03 F0 5A 5A
				/* HBM On */
				15 00 00 00 00 00 02 53 E0
				39 00 00 00 00 00 03 51 07 FF
				15 01 00 00 00 00 02 F7 07
				39 01 00 00 00 00 03 F0 A5 A5
			];
			mi,mdss-dsi-hbm-fod-off-command = [
				39 01 00 00 00 00 03 F0 5A 5A
				/* HBM off*/
				15 00 00 00 00 00 02 53 20
				39 00 00 00 00 00 03 51 07 FF
				15 01 00 00 00 00 02 F7 07
				39 01 00 00 00 00 03 F0 A5 A5
			];
			mi,mdss-dsi-hbm-fod-on-command-state = "dsi_lp_mode";
			mi,mdss-dsi-hbm-fod-off-command-state = "dsi_lp_mode";

			mi,mdss-dsi-doze-hbm-command = [
				15 01 00 00 00 00 02 60 08
				39 01 00 00 00 00 03 F0 5A 5A
				39 01 00 00 00 00 03 FC 5A 5A
				15 01 00 00 00 00 02 B0 55
				15 01 00 00 00 00 02 D1 0E
				15 01 00 00 00 00 02 F7 07
				39 01 00 00 00 00 03 FC A5 A5
				39 01 00 00 00 00 03 F0 A5 A5
				39 01 00 00 00 00 03 F0 5A 5A
				15 00 00 00 00 00 02 53 24
				15 01 00 00 00 00 02 F7 07
				39 01 00 00 00 00 03 F0 A5 A5
			];

			mi,mdss-dsi-doze-lbm-command = [
				15 01 00 00 00 00 02 60 08
				39 01 00 00 00 00 03 F0 5A 5A
				39 01 00 00 00 00 03 FC 5A 5A
				15 01 00 00 00 00 02 B0 55
				15 01 00 00 00 00 02 D1 0E
				15 01 00 00 00 00 02 F7 07
				39 01 00 00 00 00 03 FC A5 A5
				39 01 00 00 00 00 03 F0 A5 A5
				39 01 00 00 00 00 03 F0 5A 5A
				15 00 00 00 00 00 02 53 25
				15 01 00 00 00 00 02 F7 07
				39 01 00 00 00 00 03 F0 A5 A5
			];
			mi,mdss-dsi-doze-hbm-command-state = "dsi_lp_mode";
			mi,mdss-dsi-doze-lbm-command-state = "dsi_lp_mode";

			mi,mdss-dsi-doze-hbm-nolp-command = [
				39 00 00 00 00 00 03 F0 5A 5A
				39 00 00 00 00 00 03 FC 5A 5A
				15 00 00 00 00 00 02 60 08
				15 00 00 00 00 00 02 B0 55
				15 00 00 00 00 00 02 D1 53
				15 00 00 00 00 00 02 53 28
				15 00 00 00 00 00 02 F7 07
				39 00 00 00 00 00 03 FC A5 A5
				39 01 00 00 00 00 03 F0 A5 A5
			];
			mi,mdss-dsi-doze-hbm-nolp-command-state = "dsi_lp_mode";
			mi,mdss-dsi-doze-lbm-nolp-command = [
				39 00 00 00 00 00 03 F0 5A 5A
				39 00 00 00 00 00 03 FC 5A 5A
				15 00 00 00 00 00 02 60 08
				15 00 00 00 00 00 02 B0 55
				15 00 00 00 00 00 02 D1 53
				15 00 00 00 00 00 02 53 29
				15 00 00 00 00 00 02 F7 07
				39 00 00 00 00 00 03 FC A5 A5
				39 01 00 00 00 00 03 F0 A5 A5
			];
			mi,mdss-dsi-doze-lbm-nolp-command-state = "dsi_lp_mode";

			mi,mdss-dsi-flat-mode-on-command = [
				39 01 00 00 00 00 03 F0 5A 5A
				39 00 00 00 00 00 29 C6
				37 21 8D FF 55 86 00 B0
				0E FF FF 0E FF 80 91 13
				0F 0F 0F 3D 3D 3D 51 51
				51 60 60 60 66 66 66 A4
				E4 A4 08 00 80 00 00 22
				15 01 00 00 00 00 02 F7 07
				39 01 00 00 09 00 03 F0 A5 A5

			];
			mi,mdss-dsi-nature-flat-mode-on-command = [
				39 01 00 00 00 00 03 F0 5A 5A
				39 01 00 00 00 00 29 C6 37 21 E1 FF
				67 86 00 B0 0E FF FF 0E FF 80 91 13
				0E 0F 0E 3B 3D 38 4F 51 4B 5E 60 59
				63 66 5E A4 E4 A4 08 00 80 00 00 22
				39 01 00 00 00 00 02 B0 CD
				39 01 00 00 00 00 0F D3 E2 06 06 06
				92 2C 6A 80 5F 4C 40 33 FF 90
				39 01 00 00 00 00 02 F7 07
			];
			mi,mdss-dsi-flat-mode-off-command = [
				39 01 00 00 00 00 03 F0 5A 5A
				39 00 00 00 00 00 29 C6
				37 01 8D FF 55 86 00 B0
				0E FF FF 0E FF 80 91 13
				0F 0F 0F 3D 3D 3D 51 51
				51 60 60 60 66 66 66 A4
				E4 A4 08 00 80 00 00 22
				15 01 00 00 00 00 02 F7 07
				39 01 00 00 09 00 03 F0 A5 A5

			];
			mi,mdss-dsi-nature-flat-mode-off-command = [
				39 01 00 00 00 00 03 F0 5A 5A
				39 01 00 00 00 00 29 C6 37 01 E1 FF
				67 86 00 B0 0E FF FF 0E FF 80 91 13
				0E 0F 0E 3B 3D 38 4F 51 4B 5E 60 59
				63 66 5E A4 E4 A4 08 00 80 00 00 22
				39 01 00 00 00 00 02 B0 CD
				39 01 00 00 00 00 02 D3 00
				39 01 00 00 00 00 02 F7 07
			];
			mi,mdss-dsi-flat-mode-on-command-state = "dsi_lp_mode";
			mi,mdss-dsi-nature-flat-mode-on-command-state = "dsi_lp_mode";
			mi,mdss-dsi-flat-mode-off-command-state = "dsi_lp_mode";
			mi,mdss-dsi-nature-flat-mode-off-command-state = "dsi_lp_mode";
			mi,mdss-dsi-crc-off-command = [
				/* CRC Disable (Normal mode) */
				39 01 00 00 00 00 02 80 00
				39 00 00 00 00 00 03 F0 5A 5A
				/* CRC Bypass */
				39 00 00 00 00 00 02 B1 01
				39 01 00 00 00 00 03 F0 A5 A5];
			mi,mdss-dsi-crc-off-command-state = "dsi_hs_mode";

			mi,mdss-dsi-local-hbm-normal-white-1000nit-command = [
					/* Local HBM setting*/
					39 00 00 00 00 00 03 F0 5A 5A
					39 00 00 00 00 00 03 FC 5A 5A
					15 00 00 00 00 00 02 53 30
					39 00 00 00 00 00 03 51 00 00
					15 00 00 00 00 00 02 60 08
					15 00 00 00 00 00 02 F7 07
					15 00 00 00 00 00 02 B0 43
					39 00 00 00 00 00 10 D5
					02 00 00 00 00 24 49 2E
					35 CA 46 2D 09 BA 84
					39 00 00 00 00 00 02 B0 E8
					39 00 00 00 00 00 03 BB 0F FF
					39 00 00 00 00 00 02 B0 60
					39 00 00 00 00 00 10 B9
					0A 9B 0E 1B 85 0A 9B 0E
					10 7A 0A 9B 0E 10 7A
					39 00 00 00 00 00 02 B0 0E
					39 00 00 00 00 00 02 E7 02
					39 00 00 00 00 00 02 B0 36
					39 00 00 00 00 00 06 BA 00 14 00 00 18
					39 00 00 00 00 00 02 B0 6F
					39 00 00 00 00 00 13 B9
					00 40 14 02 80 52 0A 41
					48 1C 27 FF FF FF FF FF
					FF FF
					39 00 00 00 00 00 02 B0 CC
					39 00 00 00 00 00 02 D6 00
					39 00 00 00 00 00 02 B0 81
					39 00 00 00 00 00 37 B9
					16 62 14 2D 83 F2 55 47
					3A 80 08 00 80 08 00 80
					08 00 16 62 14 2D 83 F2
					55 47 3A 80 08 00 80 08
					00 80 08 00 16 62 14 2D
					83 F2 55 47 3A 80 08 00
					80 08 00 80 08 00
					39 00 00 00 00 00 02 B0 B7
					39 00 00 00 00 00 37 B9
					16 C2 1C 2D A3 F2 54 67
					36 80 08 00 80 08 00 80
					08 00 16 C2 1C 2D A3 F2
					54 67 36 80 08 00 80 08
					00 80 08 00 16 C2 1C 2D
					A3 F2 54 67 36 80 08 00
					80 08 00 80 08 00
					15 00 00 00 00 00 02 F7 07
					39 00 00 00 00 00 03 F0 A5 A5
					39 01 00 00 22 00 03 FC A5 A5
			];
			mi,mdss-dsi-local-hbm-normal-white-1000nit-command-state = "dsi_lp_mode";

			mi,mdss-dsi-local-hbm-hlpm-white-1000nit-command = [
					/* 90hz lbm nolp */
					39 00 00 00 00 00 03 F0 5A 5A
					39 00 00 00 00 00 03 FC 5A 5A
					15 00 00 00 00 00 02 60 08
					15 00 00 00 00 00 02 B0 55
					15 00 00 00 00 00 02 D1 53
					15 00 00 00 00 00 02 53 29
					15 00 00 00 00 00 02 F7 07
					39 00 00 00 00 00 03 FC A5 A5
					39 01 00 00 21 00 03 F0 A5 A5
					/* Local HBM setting*/
					39 00 00 00 00 00 03 F0 5A 5A
					39 00 00 00 00 00 03 FC 5A 5A
					15 00 00 00 00 00 02 53 30
					15 00 00 00 00 00 02 60 08
					15 00 00 00 00 00 02 F7 07
					15 00 00 00 00 00 02 B0 43
					39 00 00 00 00 00 10 D5
					02 00 00 00 00 24 49 2E
					35 CA 46 2D 09 BA 84
					39 00 00 00 00 00 02 B0 E8
					39 00 00 00 00 00 03 BB 0F FF
					39 00 00 00 00 00 02 B0 60
					39 00 00 00 00 00 10 B9
					0A 9B 0E 1B 85 0A 9B 0E
					10 7A 0A 9B 0E 10 7A
					39 00 00 00 00 00 02 B0 0E
					39 00 00 00 00 00 02 E7 02
					39 00 00 00 00 00 02 B0 36
					39 00 00 00 00 00 06 BA 00 14 00 00 18
					39 00 00 00 00 00 02 B0 6F
					39 00 00 00 00 00 13 B9
					00 40 14 02 80 52 0A 41
					48 1C 27 FF FF FF FF FF
					FF FF
					39 00 00 00 00 00 02 B0 CC
					39 00 00 00 00 00 02 D6 00
					39 00 00 00 00 00 02 B0 81
					39 00 00 00 00 00 37 B9
					16 62 14 2D 83 F2 55 47
					3A 80 08 00 80 08 00 80
					08 00 16 62 14 2D 83 F2
					55 47 3A 80 08 00 80 08
					00 80 08 00 16 62 14 2D
					83 F2 55 47 3A 80 08 00
					80 08 00 80 08 00
					39 00 00 00 00 00 02 B0 B7
					39 00 00 00 00 00 37 B9
					16 C2 1C 2D A3 F2 54 67
					36 80 08 00 80 08 00 80
					08 00 16 C2 1C 2D A3 F2
					54 67 36 80 08 00 80 08
					00 80 08 00 16 C2 1C 2D
					A3 F2 54 67 36 80 08 00
					80 08 00 80 08 00
					15 00 00 00 00 00 02 F7 07
					39 00 00 00 00 00 03 F0 A5 A5
					39 01 00 00 22 00 03 FC A5 A5
			];
			mi,mdss-dsi-local-hbm-hlpm-white-1000nit-command-state = "dsi_lp_mode";

			mi,mdss-dsi-local-hbm-normal-white-750nit-command = [
					/* Local HBM setting*/
					39 01 00 00 00 00 03 F0 5A 5A
					39 01 00 00 00 00 03 FC 5A 5A
					15 01 00 00 00 00 02 53 30
					15 01 00 00 00 00 02 60 08
					15 01 00 00 00 00 02 F7 07
					15 01 00 00 00 00 02 B0 43
					39 01 00 00 00 00 10 D5
					02 00 00 00 00 24 49 2E
					35 CA 46 2D 09 BA 84
					39 01 00 00 00 00 02 B0 E8
					39 01 00 00 00 00 03 BB 0F FF
					39 01 00 00 00 00 02 B0 60
					39 01 00 00 00 00 10 B9
					09 8A 6E A4 CA 09 8A 6E
					A0 CA 09 8A 10 44 6A
					39 01 00 00 00 00 02 B0 0E
					39 01 00 00 00 00 02 E7 02
					39 01 00 00 00 00 02 B0 36
					39 01 00 00 00 00 06 BA 00 14 00 00 18
					39 01 00 00 00 00 02 B0 6F
					39 01 00 00 00 00 13 B9
					00 40 14 02 80 52 0A 41
					48 1C 27 FF FF FF FF FF
					FF FF
					39 01 00 00 00 00 02 B0 CC
					39 01 00 00 00 00 02 D6 00
					39 01 00 00 00 00 02 B0 81
					39 01 00 00 00 00 37 B9
					16 62 14 2D 83 F2 55 47
					3A 80 08 00 80 08 00 80
					08 00 16 62 14 2D 83 F2
					55 47 3A 80 08 00 80 08
					00 80 08 00 16 62 14 2D
					83 F2 55 47 3A 80 08 00
					80 08 00 80 08 00
					39 01 00 00 00 00 02 B0 B7
					39 01 00 00 00 00 37 B9
					16 C2 1C 2D A3 F2 54 67
					36 80 08 00 80 08 00 80
					08 00 16 C2 1C 2D A3 F2
					54 67 36 80 08 00 80 08
					00 80 08 00 16 C2 1C 2D
					A3 F2 54 67 36 80 08 00
					80 08 00 80 08 00
					15 01 00 00 00 00 02 F7 07
					39 01 00 00 00 00 03 F0 A5 A5
					39 01 00 00 00 00 03 FC A5 A5
			];
			mi,mdss-dsi-local-hbm-normal-white-750nit-command-state = "dsi_lp_mode";

			mi,mdss-dsi-local-hbm-normal-white-500nit-command = [
					/* Local HBM setting*/
					39 01 00 00 00 00 03 F0 5A 5A
					39 01 00 00 00 00 03 FC 5A 5A
					15 01 00 00 00 00 02 53 30
					15 01 00 00 00 00 02 60 08
					15 01 00 00 00 00 02 F7 07
					15 01 00 00 00 00 02 B0 43
					39 01 00 00 00 00 10 D5
					02 00 00 00 00 24 49 2E
					35 CA 46 2D 09 BA 84
					39 01 00 00 00 00 02 B0 E8
					39 01 00 00 00 00 03 BB 0F FF
					39 01 00 00 00 00 02 B0 60
					39 01 00 00 00 00 10 B9
					08 79 DE FF FA 08 79 DE
					FF FA 08 79 86 AF 9A
					39 01 00 00 00 00 02 B0 0E
					39 01 00 00 00 00 02 E7 02
					39 01 00 00 00 00 02 B0 36
					39 01 00 00 00 00 06 BA 00 14 00 00 18
					39 01 00 00 00 00 02 B0 6F
					39 01 00 00 00 00 13 B9
					00 40 14 02 80 52 0A 41
					48 1C 27 FF FF FF FF FF
					FF FF
					39 01 00 00 00 00 02 B0 CC
					39 01 00 00 00 00 02 D6 00
					39 01 00 00 00 00 02 B0 81
					39 01 00 00 00 00 37 B9
					16 62 14 2D 83 F2 55 47
					3A 80 08 00 80 08 00 80
					08 00 16 62 14 2D 83 F2
					55 47 3A 80 08 00 80 08
					00 80 08 00 16 62 14 2D
					83 F2 55 47 3A 80 08 00
					80 08 00 80 08 00
					39 01 00 00 00 00 02 B0 B7
					39 01 00 00 00 00 37 B9
					16 C2 1C 2D A3 F2 54 67
					36 80 08 00 80 08 00 80
					08 00 16 C2 1C 2D A3 F2
					54 67 36 80 08 00 80 08
					00 80 08 00 16 C2 1C 2D
					A3 F2 54 67 36 80 08 00
					80 08 00 80 08 00
					15 01 00 00 00 00 02 F7 07
					39 01 00 00 00 00 03 F0 A5 A5
					39 01 00 00 00 00 03 FC A5 A5
			];
			mi,mdss-dsi-local-hbm-normal-white-500nit-command-state = "dsi_lp_mode";

			mi,mdss-dsi-local-hbm-normal-white-110nit-command = [
					/* Local HBM setting*/
					39 00 00 00 00 00 03 F0 5A 5A
					39 00 00 00 00 00 03 FC 5A 5A
					15 00 00 00 00 00 02 53 30
					15 00 00 00 00 00 02 60 08
					15 00 00 00 00 00 02 F7 07
					15 00 00 00 00 00 02 B0 43
					39 00 00 00 00 00 10 D5
					02 00 00 00 00 24 49 2E
					35 CA 46 2D 09 BA 84
					39 00 00 00 00 00 02 B0 E8
					39 00 00 00 00 00 03 BB 0F FF
					39 00 00 00 00 00 02 B0 60
					39 00 00 00 00 00 10 B9
					07 68 10 60 00 07 68 10
					60 00 06 67 E8 3B BF
					39 00 00 00 00 00 02 B0 0E
					39 00 00 00 00 00 02 E7 02
					39 00 00 00 00 00 02 B0 36
					39 00 00 00 00 00 06 BA 00 14 00 00 18
					39 00 00 00 00 00 02 B0 6F
					39 00 00 00 00 00 13 B9
					00 40 14 02 80 52 0A 41
					48 1C 27 FF FF FF FF FF
					FF FF
					39 00 00 00 00 00 02 B0 CC
					39 00 00 00 00 00 02 D6 00
					39 00 00 00 00 00 02 B0 81
					39 00 00 00 00 00 37 B9
					16 62 14 2D 83 F2 55 47
					3A 80 08 00 80 08 00 80
					08 00 16 62 14 2D 83 F2
					55 47 3A 80 08 00 80 08
					00 80 08 00 16 62 14 2D
					83 F2 55 47 3A 80 08 00
					80 08 00 80 08 00
					39 00 00 00 00 00 02 B0 B7
					39 00 00 00 00 00 37 B9
					16 C2 1C 2D A3 F2 54 67
					36 80 08 00 80 08 00 80
					08 00 16 C2 1C 2D A3 F2
					54 67 36 80 08 00 80 08
					00 80 08 00 16 C2 1C 2D
					A3 F2 54 67 36 80 08 00
					80 08 00 80 08 00
					15 00 00 00 00 00 02 F7 07
					39 00 00 00 00 00 03 F0 A5 A5
					39 01 00 00 22 00 03 FC A5 A5
			];
			mi,mdss-dsi-local-hbm-normal-white-110nit-command-state = "dsi_lp_mode";

			mi,mdss-dsi-local-hbm-hlpm-white-110nit-command = [
					/* 90hz lbm nolp */
					39 00 00 00 00 00 03 F0 5A 5A
					39 00 00 00 00 00 03 FC 5A 5A
					15 00 00 00 00 00 02 60 08
					15 00 00 00 00 00 02 B0 55
					15 00 00 00 00 00 02 D1 53
					15 00 00 00 00 00 02 53 29
					15 00 00 00 00 00 02 F7 07
					39 00 00 00 00 00 03 FC A5 A5
					39 01 00 00 21 00 03 F0 A5 A5
					/* Local HBM setting*/
					39 00 00 00 00 00 03 F0 5A 5A
					39 00 00 00 00 00 03 FC 5A 5A
					15 00 00 00 00 00 02 53 30
					15 00 00 00 00 00 02 60 08
					15 00 00 00 00 00 02 F7 07
					15 00 00 00 00 00 02 B0 43
					39 00 00 00 00 00 10 D5
					02 00 00 00 00 24 49 2E
					35 CA 46 2D 09 BA 84
					39 00 00 00 00 00 02 B0 E8
					39 00 00 00 00 00 03 BB 0F FF
					39 00 00 00 00 00 02 B0 60
					39 00 00 00 00 00 10 B9
					07 68 10 60 00 07 68 10
					60 00 06 67 E8 3B BF
					39 00 00 00 00 00 02 B0 0E
					39 00 00 00 00 00 02 E7 02
					39 00 00 00 00 00 02 B0 36
					39 00 00 00 00 00 06 BA 00 14 00 00 18
					39 00 00 00 00 00 02 B0 6F
					39 00 00 00 00 00 13 B9
					00 40 14 02 80 52 0A 41
					48 1C 27 FF FF FF FF FF
					FF FF
					39 00 00 00 00 00 02 B0 CC
					39 00 00 00 00 00 02 D6 00
					39 00 00 00 00 00 02 B0 81
					39 00 00 00 00 00 37 B9
					16 62 14 2D 83 F2 55 47
					3A 80 08 00 80 08 00 80
					08 00 16 62 14 2D 83 F2
					55 47 3A 80 08 00 80 08
					00 80 08 00 16 62 14 2D
					83 F2 55 47 3A 80 08 00
					80 08 00 80 08 00
					39 00 00 00 00 00 02 B0 B7
					39 00 00 00 00 00 37 B9
					16 C2 1C 2D A3 F2 54 67
					36 80 08 00 80 08 00 80
					08 00 16 C2 1C 2D A3 F2
					54 67 36 80 08 00 80 08
					00 80 08 00 16 C2 1C 2D
					A3 F2 54 67 36 80 08 00
					80 08 00 80 08 00
					15 00 00 00 00 00 02 F7 07
					39 00 00 00 00 00 03 F0 A5 A5
					39 01 00 00 22 00 03 FC A5 A5
			];
			mi,mdss-dsi-local-hbm-hlpm-white-110nit-command-state = "dsi_lp_mode";

			mi,mdss-dsi-local-hbm-normal-green-500nit-command = [
					/* Local HBM setting*/
					39 01 00 00 00 00 03 F0 5A 5A
					39 01 00 00 00 00 03 FC 5A 5A
					15 01 00 00 00 00 02 53 30
					15 01 00 00 00 00 02 60 08
					15 01 00 00 00 00 02 F7 07
					15 01 00 00 00 00 02 B0 43
					39 01 00 00 00 00 10 D5
					02 00 00 00 00 24 49 2E
					35 CA 46 2D 09 BA 84
					39 01 00 00 00 00 02 B0 E8
					39 01 00 00 00 00 03 BB 0F FF
					39 01 00 00 00 00 02 B0 60
					39 01 00 00 00 00 10 B9
					00 80 00 85 00 00 80 00
					85 00 00 80 00 25 00
					39 01 00 00 00 00 02 B0 0E
					39 01 00 00 00 00 02 E7 02
					39 01 00 00 00 00 02 B0 36
					39 01 00 00 00 00 06 BA 00 14 00 00 18
					39 01 00 00 00 00 02 B0 6F
					39 01 00 00 00 00 13 B9
					00 40 14 02 80 52 0A 41
					48 1C 27 FF FF FF FF FF
					FF FF
					39 01 00 00 00 00 02 B0 CC
					39 01 00 00 00 00 02 D6 00
					39 01 00 00 00 00 02 B0 81
					39 01 00 00 00 00 37 B9
					16 62 14 2D 83 F2 55 47
					3A 80 08 00 80 08 00 80
					08 00 16 62 14 2D 83 F2
					55 47 3A 80 08 00 80 08
					00 80 08 00 16 62 14 2D
					83 F2 55 47 3A 80 08 00
					80 08 00 80 08 00
					39 01 00 00 00 00 02 B0 B7
					39 01 00 00 00 00 37 B9
					16 C2 1C 2D A3 F2 54 67
					36 80 08 00 80 08 00 80
					08 00 16 C2 1C 2D A3 F2
					54 67 36 80 08 00 80 08
					00 80 08 00 16 C2 1C 2D
					A3 F2 54 67 36 80 08 00
					80 08 00 80 08 00
					15 01 00 00 00 00 02 F7 07
					39 01 00 00 00 00 03 F0 A5 A5
					39 01 00 00 00 00 03 FC A5 A5
			];
			mi,mdss-dsi-local-hbm-normal-green-500nit-command-state = "dsi_lp_mode";

			mi,mdss-dsi-local-hbm-off-to-normal-command = [
					/* Local HBM setting*/
					39 00 00 00 00 00 03 F0 5A 5A
					15 00 00 00 00 00 02 53 20
					39 01 00 00 00 00 03 F0 A5 A5
			];
			mi,mdss-dsi-local-hbm-off-to-normal-command-state = "dsi_lp_mode";

			mi,mdss-dsi-local-hbm-off-to-hbm-command = [
					/* Local HBM setting*/
					39 00 00 00 00 00 03 F0 5A 5A
					15 00 00 00 00 00 02 53 E8
					39 00 00 00 00 00 03 51 00 00
					15 00 00 00 00 00 02 F7 07
					39 01 00 00 00 00 03 F0 A5 A5
			];
			mi,mdss-dsi-local-hbm-off-to-hbm-command-state = "dsi_lp_mode";

			mi,mdss-dsi-local-hbm-off-to-hlpm-command = [
					/* Local HBM setting*/
					15 00 00 00 00 00 02 60 08
					39 00 00 00 00 00 03 F0 5A 5A
					39 00 00 00 00 00 03 FC 5A 5A
					15 00 00 00 00 00 02 B0 55
					15 00 00 00 00 00 02 D1 0E
					15 00 00 00 00 00 02 F7 07
					39 00 00 00 00 00 03 FC A5 A5
					39 01 00 00 00 00 03 F0 A5 A5
					39 00 00 00 00 00 03 F0 5A 5A
					15 00 00 00 00 00 02 53 24
					15 00 00 00 00 00 02 F7 07
					39 01 00 00 00 00 03 F0 A5 A5
			];
			mi,mdss-dsi-local-hbm-off-to-hlpm-command-state = "dsi_lp_mode";

			mi,mdss-dsi-local-hbm-off-to-llpm-command = [
					/* Local HBM setting*/
					15 00 00 00 00 00 02 60 08
					39 00 00 00 00 00 03 F0 5A 5A
					39 00 00 00 00 00 03 FC 5A 5A
					15 00 00 00 00 00 02 B0 55
					15 00 00 00 00 00 02 D1 0E
					15 00 00 00 00 00 02 F7 07
					39 00 00 00 00 00 03 FC A5 A5
					39 01 00 00 00 00 03 F0 A5 A5
					39 00 00 00 00 00 03 F0 5A 5A
					15 00 00 00 00 00 02 53 25
					15 00 00 00 00 00 02 F7 07
					39 01 00 00 00 00 03 F0 A5 A5
			];
			mi,mdss-dsi-local-hbm-off-to-llpm-command-state = "dsi_lp_mode";

			mi,mdss-dsi-spr-1d-rendering-command = [
					39 00 00 00 00 00 03 F0 5A 5A
					39 00 00 00 00 00 08 B3 00 00 D8 D8 C0 C0 71         /* 1D Rendering */
					39 01 00 00 00 00 03 F0 A5 A5
			];
			mi,mdss-dsi-spr-1d-rendering-command-state = "dsi_lp_mode";

			mi,mdss-dsi-spr-2d-rendering-command = [
					39 00 00 00 00 00 03 F0 5A 5A
					39 00 00 00 00 00 08 B3 00 00 D8 D8 FF FF 40         /* 2D Rendering */
					39 01 00 00 00 00 03 F0 A5 A5
			];
			mi,mdss-dsi-spr-2d-rendering-command-state = "dsi_lp_mode";

			mi,mdss-dsi-color-invert-on-command = [05 01 00 00 00 00 01 21];
			mi,mdss-dsi-color-invert-on-command-state = "dsi_lp_mode";

			mi,mdss-dsi-color-invert-off-command = [05 01 00 00 00 00 01 20];
			mi,mdss-dsi-color-invert-off-command-state = "dsi_lp_mode";
		};
	};
};
